VERSION ""

NS_ :

BS_:

BU_: Airbag_MQB BAP_Tester_MQB BMS_MQB Datenlogger_MQB Gateway_MQB Getriebe_DQ_Hybrid_MQB Getriebe_DQ_MQB LEH_MQB Motor_Diesel_MQB Motor_Hybrid_MQB Motor_Otto_MQB SAK_MQB Waehlhebel_MQB Vector__XXX l c i XXX

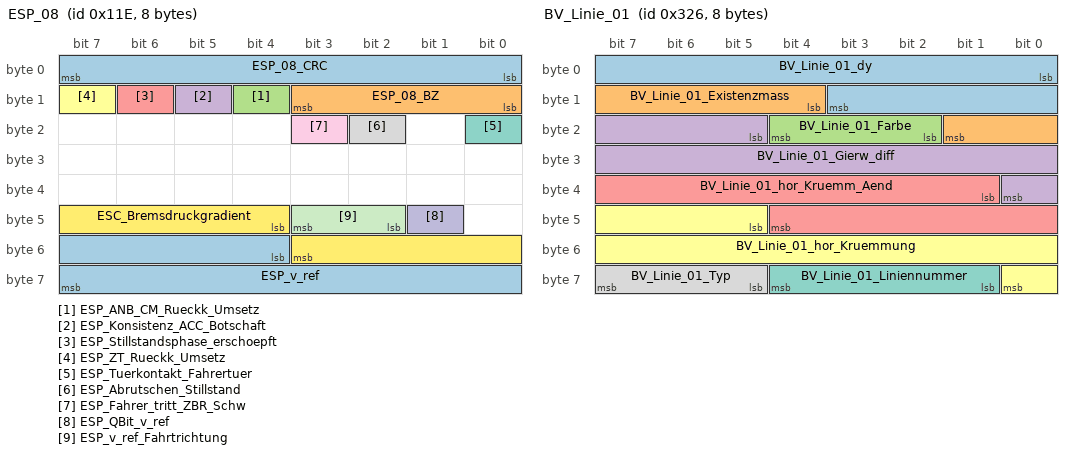
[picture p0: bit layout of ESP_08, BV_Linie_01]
BO_ 286 ESP_08: 8 Gateway_MQB
 SG_ ESP_08_CRC : 0|8@1+ (1,0) [0|255] ""  XXX
 SG_ ESP_08_BZ : 8|4@1+ (1,0) [0|15] ""  XXX
 SG_ ESP_ANB_CM_Rueckk_Umsetz : 12|1@1+ (1.0,0.0) [0.0|1] ""  XXX
 SG_ ESP_Konsistenz_ACC_Botschaft : 13|1@1+ (1.0,0.0) [0.0|1] ""  XXX
 SG_ ESP_Stillstandsphase_erschoepft : 14|1@1+ (1.0,0.0) [0.0|1] ""  XXX
 SG_ ESP_ZT_Rueckk_Umsetz : 15|1@1+ (1.0,0.0) [0.0|1] ""  XXX
 SG_ ESP_Tuerkontakt_Fahrertuer : 16|1@1+ (1.0,0.0) [0.0|1] ""  XXX
 SG_ ESP_Abrutschen_Stillstand : 18|1@1+ (1.0,0.0) [0.0|1] ""  XXX
 SG_ ESP_Fahrer_tritt_ZBR_Schw : 19|1@1+ (1.0,0.0) [0.0|1] ""  XXX
 SG_ ESP_QBit_v_ref : 41|1@1+ (1.0,0.0) [0.0|1] ""  XXX
 SG_ ESP_v_ref_Fahrtrichtung : 42|2@1+ (1.0,0.0) [0.0|3] ""  XXX
 SG_ ESC_Bremsdruckgradient : 44|8@1+ (10,0) [0|2500] "Unit_BarPerSecon"  XXX
 SG_ ESP_v_ref : 52|12@1+ (0.125,0) [0.000|511.500] "Unit_KiloMeterPerHour"  XXX

BO_ 919 LDW_02: 8 XXX
 SG_ LDW_Gong : 12|2@1+ (1,0) [0|3] ""  XXX
 SG_ LDW_Frueh_Spaet : 14|2@1+ (1,0) [0|3] ""  XXX
 SG_ LDW_Texte : 16|4@1+ (1,0) [0|15] ""  XXX
 SG_ LDW_Seite_DLCTLC : 20|1@1+ (1,0) [0|1] ""  XXX
 SG_ LDW_Lernmodus : 21|3@1+ (1,0) [0|7] ""  XXX
 SG_ LDW_Anlaufsp_VLR : 24|4@1+ (1,0) [0|15] ""  XXX
 SG_ LDW_Vib_Amp_VLR : 28|4@1+ (1,0) [0|15] ""  XXX
 SG_ LDW_Anlaufzeit_VLR : 32|4@1+ (1,0) [0|15] ""  XXX
 SG_ LDW_Lernmodus_rechts : 36|2@1+ (1,0) [0|3] ""  XXX
 SG_ LDW_Lernmodus_links : 38|2@1+ (1,0) [0|3] ""  XXX
 SG_ LDW_DLC : 40|8@1+ (0.01,-1.25) [-1.25|1.25] "Unit_Meter"  XXX
 SG_ LDW_TLC : 48|5@1+ (0.1,0) [0|3] "Unit_Secon"  XXX
 SG_ LDW_Warnung_links : 56|1@1+ (1,0) [0|1] ""  XXX
 SG_ LDW_Warnung_rechts : 57|1@1+ (1,0) [0|1] ""  XXX
 SG_ LDW_Codierinfo_fuer_VLR : 58|2@1+ (1,0) [0|3] ""  XXX
 SG_ LDW_Frontscheibenheizung_aktiv : 60|1@1+ (1,0) [0|1] ""  XXX
 SG_ LDW_Status_LED_gelb : 61|1@1+ (1,0) [0|1] ""  XXX
 SG_ LDW_Status_LED_gruen : 62|1@1+ (1,0) [0|1] ""  XXX
 SG_ LDW_KD_Fehler : 63|1@1+ (1,0) [0|1] ""  XXX

BO_ 806 BV_Linie_01: 8 XXX
 SG_ BV_Linie_01_dy : 0|12@1+ (0.00390625,-8) [-8.00000000|7.99609375] "Unit_Meter" XXX
 SG_ BV_Linie_01_Existenzmass : 12|6@1+ (0.015625,0) [0.000000|0.984375] "Unit_Meter" XXX
 SG_ BV_Linie_01_Farbe : 18|3@1+ (1.0,0.0) [0.0|7] "" XXX
 SG_ BV_Linie_01_Gierw_diff : 21|12@1+ (0.00048828125,-1) [-1.00000000000|0.99951171875] "Unit_Radia" XXX
 SG_ BV_Linie_01_hor_Kruemm_Aend : 33|12@1+ (1,-2047) [-2047|2048] "" XXX
 SG_ BV_Linie_01_hor_Kruemmung : 45|12@1+ (1,-2047) [-2047|2048] "" XXX
 SG_ BV_Linie_01_Liniennummer : 57|4@1+ (1,0) [1|15] "" XXX
 SG_ BV_Linie_01_Typ : 61|3@1+ (1.0,0.0) [0.0|7] "" XXX

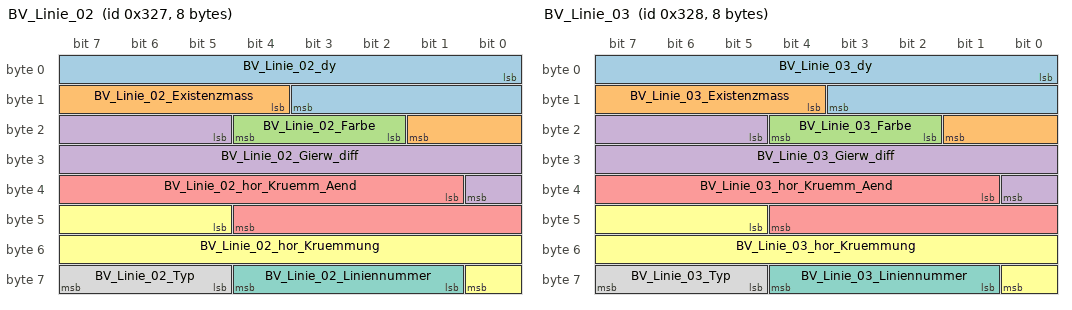
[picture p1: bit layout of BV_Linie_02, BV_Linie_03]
BO_ 807 BV_Linie_02: 8 XXX
 SG_ BV_Linie_02_dy : 0|12@1+ (0.00390625,-8) [-8.00000000|7.99609375] "Unit_Meter" XXX
 SG_ BV_Linie_02_Existenzmass : 12|6@1+ (0.015625,0) [0.000000|0.984375] "Unit_Meter" XXX
 SG_ BV_Linie_02_Farbe : 18|3@1+ (1.0,0.0) [0.0|7] "" XXX
 SG_ BV_Linie_02_Gierw_diff : 21|12@1+ (0.00048828125,-1) [-1.00000000000|0.99951171875] "Unit_Radia" XXX
 SG_ BV_Linie_02_hor_Kruemm_Aend : 33|12@1+ (1,-2047) [-2047|2048] "" XXX
 SG_ BV_Linie_02_hor_Kruemmung : 45|12@1+ (1,-2047) [-2047|2048] "" XXX
 SG_ BV_Linie_02_Liniennummer : 57|4@1+ (1,0) [1|15] "" XXX
 SG_ BV_Linie_02_Typ : 61|3@1+ (1.0,0.0) [0.0|7] "" XXX

BO_ 808 BV_Linie_03: 8 XXX
 SG_ BV_Linie_03_dy : 0|12@1+ (0.00390625,-8) [-8.00000000|7.99609375] "Unit_Meter" XXX
 SG_ BV_Linie_03_Existenzmass : 12|6@1+ (0.015625,0) [0.000000|0.984375] "Unit_Meter" XXX
 SG_ BV_Linie_03_Farbe : 18|3@1+ (1.0,0.0) [0.0|7] "" XXX
 SG_ BV_Linie_03_Gierw_diff : 21|12@1+ (0.00048828125,-1) [-1.00000000000|0.99951171875] "Unit_Radia" XXX
 SG_ BV_Linie_03_hor_Kruemm_Aend : 33|12@1+ (1,-2047) [-2047|2048] "" XXX
 SG_ BV_Linie_03_hor_Kruemmung : 45|12@1+ (1,-2047) [-2047|2048] "" XXX
 SG_ BV_Linie_03_Liniennummer : 57|4@1+ (1,0) [1|15] "" XXX
 SG_ BV_Linie_03_Typ : 61|3@1+ (1.0,0.0) [0.0|7] "" XXX

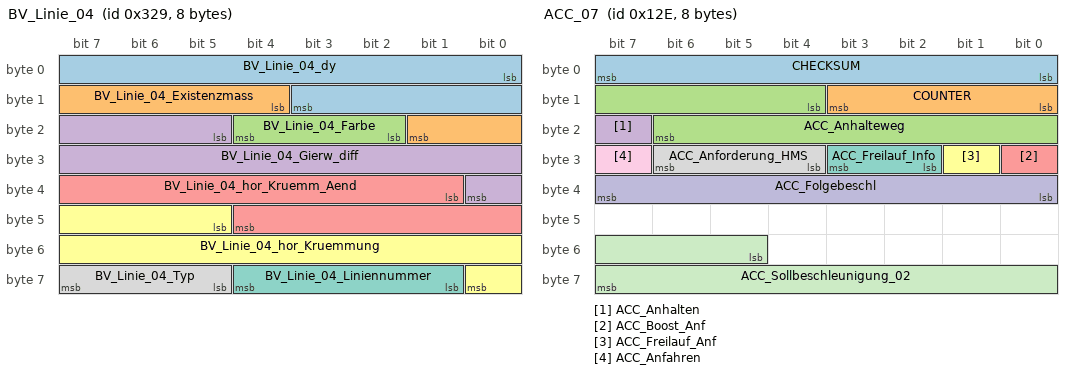
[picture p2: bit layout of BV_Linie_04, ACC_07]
BO_ 809 BV_Linie_04: 8 XXX
 SG_ BV_Linie_04_dy : 0|12@1+ (0.00390625,-8) [-8.00000000|7.99609375] "Unit_Meter" XXX
 SG_ BV_Linie_04_Existenzmass : 12|6@1+ (0.015625,0) [0.000000|0.984375] "Unit_Meter" XXX
 SG_ BV_Linie_04_Farbe : 18|3@1+ (1.0,0.0) [0.0|7] "" XXX
 SG_ BV_Linie_04_Gierw_diff : 21|12@1+ (0.00048828125,-1) [-1.00000000000|0.99951171875] "Unit_Radia" XXX
 SG_ BV_Linie_04_hor_Kruemm_Aend : 33|12@1+ (1,-2047) [-2047|2048] "" XXX
 SG_ BV_Linie_04_hor_Kruemmung : 45|12@1+ (1,-2047) [-2047|2048] "" XXX
 SG_ BV_Linie_04_Liniennummer : 57|4@1+ (1,0) [1|15] "" XXX
 SG_ BV_Linie_04_Typ : 61|3@1+ (1.0,0.0) [0.0|7] "" XXX

BO_ 385 VZE_01: 8 XXX
 SG_ VZE_Anzeigemodus : 0|2@1+ (1.0,0.0) [0.0|3] "" XXX
 SG_ VZE_Hinweistext : 2|3@1+ (1,0) [1|7] "" XXX
 SG_ VZE_Akustik_Limitwechsel : 5|1@1+ (1.0,0.0) [0.0|1] "" XXX
 SG_ VZE_Modus_OptischeWarnung : 6|1@1+ (1.0,0.0) [0.0|1] "" XXX
 SG_ VZE_Anzeigeunterdrueck_Zeichen_3 : 9|1@1+ (1.0,0.0) [0.0|1] "" XXX
 SG_ VZE_Anzeigeunterdrueck_Zeichen_2 : 10|1@1+ (1.0,0.0) [0.0|1] "" XXX
 SG_ VZE_Verkehrszeichen_1 : 11|8@1+ (1,0) [1|255] "" XXX
 SG_ VZE_Verkehrszeichen_2 : 19|8@1+ (1,0) [1|255] "" XXX
 SG_ VZE_Verkehrszeichen_3 : 27|8@1+ (1,0) [1|255] "" XXX
 SG_ VZE_Warnung_Verkehrszeichen_1 : 35|1@1+ (1.0,0.0) [0.0|1] "" XXX
 SG_ VZE_Warnung_Verkehrszeichen_2 : 36|1@1+ (1.0,0.0) [0.0|1] "" XXX
 SG_ VZE_Warnung_Verkehrszeichen_3 : 37|1@1+ (1.0,0.0) [0.0|1] "" XXX
 SG_ VZE_Zusatzschild_1 : 38|4@1+ (1,0) [1|15] "" XXX
 SG_ VZE_Zusatzschild_2 : 42|4@1+ (1,0) [1|15] "" XXX
 SG_ VZE_Zusatzschild_3 : 46|4@1+ (1,0) [1|15] "" XXX
 SG_ VZE_Anzeigeunterdrueck_Zeichen_1 : 50|1@1+ (1.0,0.0) [0.0|1] "" XXX
 SG_ VZE_Zeichen_01_KameraWied : 51|1@1+ (1.0,0.0) [0.0|1] "" XXX
 SG_ VZE_Zeichen_02_KameraWied : 52|1@1+ (1.0,0.0) [0.0|1] "" XXX
 SG_ VZE_Zeichen_03_KameraWied : 53|1@1+ (1.0,0.0) [0.0|1] "" XXX
 SG_ VZE_Zeichen_01_Kamera : 54|1@1+ (1.0,0.0) [0.0|1] "" XXX
 SG_ VZE_Zeichen_01_Karte : 55|1@1+ (1.0,0.0) [0.0|1] "" XXX
 SG_ VZE_Zeichen_01_Gesetz : 56|1@1+ (1.0,0.0) [0.0|1] "" XXX
 SG_ VZE_Zeichen_02_Kamera : 57|1@1+ (1.0,0.0) [0.0|1] "" XXX
 SG_ VZE_Zeichen_02_Karte : 58|1@1+ (1.0,0.0) [0.0|1] "" XXX
 SG_ VZE_Zeichen_02_Gesetz : 59|1@1+ (1.0,0.0) [0.0|1] "" XXX
 SG_ VZE_Zeichen_03_Kamera : 60|1@1+ (1.0,0.0) [0.0|1] "" XXX
 SG_ VZE_Zeichen_03_Karte : 61|1@1+ (1.0,0.0) [0.0|1] "" XXX
 SG_ VZE_Zeichen_03_Gesetz : 62|1@1+ (1.0,0.0) [0.0|1] "" XXX
 SG_ VZE_Gong : 63|1@1+ (1.0,0.0) [0.0|1] "" XXX

BO_ 668 VZE_02: 8 XXX
 SG_ VZE_Akustik_Limitwechsel_Status : 5|1@1+ (1.0,0.0) [0.0|1] "" XXX
 SG_ VZE_SLWF_Status : 6|2@1+ (1.0,0.0) [0.0|3] "" XXX
 SG_ VZE_Anzeigeunterdrueck_Zeichen_5 : 8|1@1+ (1.0,0.0) [0.0|1] "" XXX
 SG_ VZE_Zeichen_05_KameraWied : 9|1@1+ (1.0,0.0) [0.0|1] "" XXX
 SG_ VZE_Zeichen_05_Kamera : 10|1@1+ (1.0,0.0) [0.0|1] "" XXX
 SG_ VZE_Verkehrszeichen_4 : 11|8@1+ (1,0) [1|255] "" XXX
 SG_ VZE_Verkehrszeichen_5 : 19|8@1+ (1,0) [1|255] "" XXX
 SG_ VZE_Anhaenger_Vmax : 27|4@1+ (10,10) [10|140] "Unit_KiloMeterPerHour" XXX
 SG_ VZE_Zeichen_04_Gesetz : 31|1@1+ (1.0,0.0) [0.0|1] "" XXX
 SG_ VZE_Zeichen_04_Kamera : 32|1@1+ (1.0,0.0) [0.0|1] "" XXX
 SG_ VZE_Zeichen_04_KameraWied : 33|1@1+ (1.0,0.0) [0.0|1] "" XXX
 SG_ VZE_Zeichen_04_Karte : 34|1@1+ (1.0,0.0) [0.0|1] "" XXX
 SG_ VZE_Warnung_Verkehrszeichen_4 : 35|1@1+ (1.0,0.0) [0.0|1] "" XXX
 SG_ VZE_Warnung_Verkehrszeichen_5 : 36|1@1+ (1.0,0.0) [0.0|1] "" XXX
 SG_ VZE_Zeichen_05_Gesetz : 37|1@1+ (1.0,0.0) [0.0|1] "" XXX
 SG_ VZE_Zusatzschild_4 : 38|4@1+ (1,0) [1|15] "" XXX
 SG_ VZE_Zusatzschild_5 : 42|4@1+ (1,0) [1|15] "" XXX
 SG_ VZE_Baustelle : 46|2@1+ (1.0,0.0) [0.0|3] "" XXX
 SG_ VZE_Zeichen_05_Karte : 48|1@1+ (1.0,0.0) [0.0|1] "" XXX
 SG_ VZE_Zeichen_05_Entfernung : 49|7@1+ (1,0) [1|127] "Unit_Meter" XXX
 SG_ VZE_Zeichen_05_Entfernung_StdA : 56|7@1+ (1,0) [1|127] "Unit_Meter" XXX
 SG_ VZE_Anzeigeunterdrueck_Zeichen_4 : 63|1@1+ (1.0,0.0) [0.0|1] "" XXX

BO_ 780 ACC_02: 8 XXX
 SG_ CHECKSUM : 0|8@1+ (1,0) [0|255] ""  XXX
 SG_ COUNTER : 8|4@1+ (1,0) [0|15] ""  XXX
 SG_ ACC_Wunschgeschw_02 : 12|10@1+ (0.32,0) [0|327.04] "Unit_KiloMeterPerHour"  XXX
 SG_ ACC_Status_Prim_Anz : 22|2@1+ (1,0) [0|3] ""  XXX
 SG_ ACC_Abstandsindex : 24|10@1+ (1,0) [1|1021] ""  XXX
 SG_ ACC_Akustik_02 : 34|2@1+ (1,0) [0|3] ""  XXX
 SG_ ACC_Warnung_Verkehrszeichen_1 : 36|1@1+ (1,0) [0|1] ""  XXX
 SG_ ACC_Gesetzte_Zeitluecke : 37|3@1+ (1,0) [0|7] ""  XXX
 SG_ ACC_Optischer_Fahrerhinweis : 40|1@1+ (1,0) [0|1] ""  XXX
 SG_ ACC_Typ_Tachokranz : 41|1@1+ (1,0) [0|1] ""  XXX
 SG_ ACC_Anzeige_Zeitluecke : 42|1@1+ (1,0) [0|1] ""  XXX
 SG_ ACC_Tachokranz : 43|1@1+ (1,0) [0|1] ""  XXX
 SG_ ACC_Display_Prio : 44|2@1+ (1,0) [0|3] ""  XXX
 SG_ ACC_Relevantes_Objekt : 46|2@1+ (1,0) [0|3] ""  XXX
 SG_ ACC_Texte_Primaeranz : 48|7@1+ (1,0) [0|127] ""  XXX
 SG_ ACC_Wunschgeschw_erreicht : 55|1@1+ (1,0) [0|1] ""  XXX
 SG_ ACC_Typ_Tachokranz_unten : 60|1@1+ (1,0) [0|1] ""  XXX
 SG_ ACC_Status_Anzeige : 61|3@1+ (1,0) [0|7] ""  XXX

BO_ 302 ACC_07: 8 XXX
 SG_ CHECKSUM : 0|8@1+ (1,0) [0|255] ""  XXX
 SG_ COUNTER : 8|4@1+ (1,0) [0|15] ""  XXX
 SG_ ACC_Anhalteweg : 12|11@1+ (0.01,0) [0|20.45] "Unit_Meter"  XXX
 SG_ ACC_Anhalten : 23|1@1+ (1,0) [0|1] ""  XXX
 SG_ ACC_Boost_Anf : 24|1@1+ (1,0) [0|1] ""  XXX
 SG_ ACC_Freilauf_Anf : 25|1@1+ (1,0) [0|1] ""  XXX
 SG_ ACC_Freilauf_Info : 26|2@1+ (1,0) [0|3] ""  XXX
 SG_ ACC_Anforderung_HMS : 28|3@1+ (1,0) [0|7] ""  XXX
 SG_ ACC_Anfahren : 31|1@1+ (1,0) [0|1] ""  XXX
 SG_ ACC_Folgebeschl : 32|8@1+ (0.03,-4.6) [-4.6|2.99] "Unit_MeterPerSeconSquar"  XXX
 SG_ ACC_Sollbeschleunigung_02 : 53|11@1+ (0.005,-7.22) [-7.22|3.005] "Unit_MeterPerSeconSquar"  XXX

BO_ 264 Fahrwerk_01: 8 XXX
 SG_ Fahrwerk_01_BZ : 8|4@1+ (1,0) [0|15] "" XXX
 SG_ Fahrwerk_01_CRC : 0|8@1+ (1,0) [0|255] "" XXX

BO_ 695 RCTA_01: 8 XXX
 SG_ RCTA_01_BZ : 8|4@1+ (1,0) [0|15] "" XXX
 SG_ RCTA_01_CRC : 0|8@1+ (1,0) [0|255] "" XXX

BO_ 783 SWA_01: 8 Gateway_MQB
 SG_ CHECKSUM : 0|8@1+ (1,0) [0|255] ""  XXX
 SG_ COUNTER : 8|4@1+ (1,0) [0|15] ""  XXX
 SG_ SWA_Anzeigen : 12|4@1+ (1,0) [0|15] ""  XXX
 SG_ SWA_Blindheit_erkannt : 16|1@1+ (1,0) [0|1] ""  XXX
 SG_ SWA_rel_Nichtverf : 17|1@1+ (1,0) [0|1] ""  XXX
 SG_ SWA_rel_Fehler : 18|1@1+ (1,0) [0|1] ""  XXX
 SG_ SWA_Sta_aktiv : 19|1@1+ (1,0) [0|1] ""  XXX
 SG_ SWA_Sta_passiv : 20|1@1+ (1,0) [0|1] ""  XXX
 SG_ SWA_FT_RueckLED : 21|1@1+ (1,0) [0|1] ""  XXX
 SG_ ASW_Status : 22|2@1+ (1,0) [0|3] ""  XXX
 SG_ SWA_Standziele_li : 24|1@1+ (1,0) [0|1] ""  XXX
 SG_ SWA_Kolonne_li : 25|1@1+ (1,0) [0|1] ""  XXX
 SG_ SWA_Infostufe_SWA_li : 26|1@1+ (1,0) [0|1] ""  XXX
 SG_ SWA_Warnung_SWA_li : 27|1@1+ (1,0) [0|1] ""  XXX
 SG_ ASW_Warnung_FS : 28|1@1+ (1,0) [0|1] ""  XXX
 SG_ ASW_Warnung_BFS : 29|1@1+ (1,0) [0|1] ""  XXX
 SG_ ASW_Kombitexte : 30|3@1+ (1,0) [0|7] ""  XXX
 SG_ SWA_Kolonne_mi : 33|1@1+ (1,0) [0|1] ""  XXX
 SG_ SWA_Standziele_re : 40|1@1+ (1,0) [0|1] ""  XXX
 SG_ SWA_Kolonne_re : 41|1@1+ (1,0) [0|1] ""  XXX
 SG_ SWA_Infostufe_SWA_re : 42|1@1+ (1,0) [0|1] ""  XXX
 SG_ SWA_Warnung_SWA_re : 43|1@1+ (1,0) [0|1] ""  XXX
 SG_ HRE_Anzeigetexte : 44|4@1+ (1,0) [0|15] ""  XXX
 SG_ SWA_Gischtzaehler : 48|7@1+ (1,0) [0|100] "Unit_PerCent"  XXX
 SG_ Heckradar_Kombitexte : 56|5@1+ (1,0) [0|31] ""  XXX
 SG_ RCTA_Kombitexte : 61|3@1+ (1,0) [0|7] ""  XXX

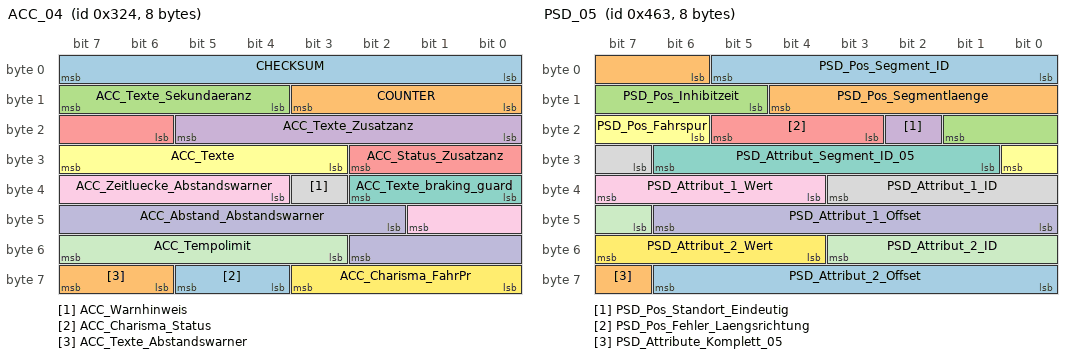
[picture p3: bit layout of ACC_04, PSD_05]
BO_ 804 ACC_04: 8 XXX
 SG_ CHECKSUM : 0|8@1+ (1,0) [0|255] ""  XXX
 SG_ COUNTER : 8|4@1+ (1,0) [0|15] ""  XXX
 SG_ ACC_Texte_Sekundaeranz : 12|4@1+ (1,0) [0|15] ""  XXX
 SG_ ACC_Texte_Zusatzanz : 16|6@1+ (1,0) [0|63] ""  XXX
 SG_ ACC_Status_Zusatzanz : 22|5@1+ (1,0) [0|31] ""  XXX
 SG_ ACC_Texte : 27|5@1+ (1,0) [0|31] ""  XXX
 SG_ ACC_Texte_braking_guard : 32|3@1+ (1,0) [0|7] ""  XXX
 SG_ ACC_Warnhinweis : 35|1@1+ (1,0) [0|1] ""  XXX
 SG_ ACC_Zeitluecke_Abstandswarner : 36|6@1+ (0.1,0) [0|6] "Unit_Secon"  XXX
 SG_ ACC_Abstand_Abstandswarner : 42|9@1+ (1,0) [0|508] ""  XXX
 SG_ ACC_Tempolimit : 51|5@1+ (1,0) [0|31] ""  XXX
 SG_ ACC_Charisma_FahrPr : 56|4@1+ (1,0) [0|15] ""  XXX
 SG_ ACC_Charisma_Status : 60|2@1+ (1,0) [0|3] ""  XXX
 SG_ ACC_Texte_Abstandswarner : 62|2@1+ (1,0) [0|3] ""  XXX

BO_ 917 LWR_AFS_01: 8 XXX

BO_ 991 Gateway_76: 8 XXX

BO_ 997 TSG_FT_02: 8 XXX
 SG_ TSG_FT_02_BZ : 8|4@1+ (1,0) [0|15] "" XXX
 SG_ TSG_FT_02_CRC : 0|8@1+ (1,0) [0|255] "" XXX

BO_ 1175 Parkhilfe_01: 8 XXX
 SG_ PH_Visualisierung : 0|3@1+ (1.0,0.0) [0.0|7] "" XXX
 SG_ PDC_Tonausgabe_Front : 4|4@1+ (1.0,0.0) [0.0|15] "" XXX
 SG_ PDC_Tonausgabe_Heck : 8|4@1+ (1.0,0.0) [0.0|15] "" XXX
 SG_ PH_nachtr_Stopp_Anf : 12|1@1+ (1.0,0.0) [0.0|1] "" XXX
 SG_ PH_Abschaltursache : 13|3@1+ (1.0,0.0) [0.0|7] "" XXX
 SG_ PH_Opt_Anzeige_V_ein : 16|1@1+ (1.0,0.0) [0.0|1] "" XXX
 SG_ PH_Opt_Anzeige_H_ein : 17|1@1+ (1.0,0.0) [0.0|1] "" XXX
 SG_ PH_Opt_Anz_V_Hindernis : 18|1@1+ (1.0,0.0) [0.0|1] "" XXX
 SG_ PH_Opt_Anz_H_Hindernis : 19|1@1+ (1.0,0.0) [0.0|1] "" XXX
 SG_ PH_Tongeber_V_aktiv : 20|1@1+ (1.0,0.0) [0.0|1] "" XXX
 SG_ PH_Tongeber_H_aktiv : 21|1@1+ (1.0,0.0) [0.0|1] "" XXX
 SG_ PH_Tongeber_mute : 22|1@1+ (1.0,0.0) [0.0|1] "" XXX
 SG_ PH_Anf_Audioabsenkung : 23|1@1+ (1.0,0.0) [0.0|1] "" XXX
 SG_ PH_Tongeber_H_verfuegbar : 24|1@1+ (1.0,0.0) [0.0|1] "" XXX
 SG_ PLA_Anf_Aufschaltung_RVC : 25|1@1+ (1.0,0.0) [0.0|1] "" XXX
 SG_ PH_Taster : 28|2@1+ (1.0,0.0) [0.0|3] "" XXX
 SG_ PH_Anf_Verdeck : 30|2@1+ (1.0,0.0) [0.0|3] "" XXX
 SG_ PH_Frequenz_hinten : 32|4@1+ (1,0) [0|15] "" XXX
 SG_ PH_Lautstaerke_hinten : 36|4@1+ (1,0) [0|15] "" XXX
 SG_ PH_Frequenz_vorn : 40|4@1+ (1,0) [0|15] "" XXX
 SG_ PH_Lautstaerke_vorn : 44|4@1+ (1,0) [0|15] "" XXX
 SG_ PH_StartStopp_Info : 49|2@1+ (1.0,0.0) [0.0|3] "" XXX
 SG_ PH_Stoermeldung : 52|4@1+ (1.0,0.0) [0.0|15] "" XXX
 SG_ PH_defekt : 56|1@1+ (1.0,0.0) [0.0|1] "" XXX
 SG_ PH_gestoert : 57|1@1+ (1.0,0.0) [0.0|1] "" XXX
 SG_ PH_Systemzustand : 58|3@1+ (1.0,0.0) [0.0|7] "" XXX
 SG_ PH_Display_Kundenwunsch : 61|2@1+ (1.0,0.0) [0.0|3] "" XXX

BO_ 427 ESP_33: 8 Gateway_MQB
 SG_ CHECKSUM : 0|8@1+ (1,0) [0|255] ""  Motor_Hybrid_MQB,Motor_Otto_MQB
 SG_ COUNTER : 8|4@1+ (1,0) [0|15] ""  Motor_Hybrid_MQB,Motor_Otto_MQB
 SG_ ESC_AHW_aktiv : 12|3@1+ (1,0) [0|7] ""  Motor_Hybrid_MQB,Motor_Otto_MQB
 SG_ ESC_AHW_nicht_verfuegbar : 15|1@1+ (1,0) [0|1] ""  Vector__XXX
 SG_ ESC_ANB_CM_aktiv : 16|2@1+ (1,0) [0|3] ""  Motor_Hybrid_MQB,Motor_Otto_MQB
 SG_ ESC_ANB_CM_nicht_verfuegbar : 18|1@1+ (1,0) [0|1] ""  Vector__XXX
 SG_ ESC_Warnruck_aktiv : 19|4@1+ (1,0) [0|15] ""  Motor_Hybrid_MQB,Motor_Otto_MQB
 SG_ ESC_Warnruck_nicht_verfuegbar : 23|1@1+ (1,0) [0|1] ""  Vector__XXX
 SG_ ESC_Prefill_aktiv : 24|1@1+ (1,0) [0|1] ""  Vector__XXX
 SG_ ESC_Prefill_nicht_verfuegbar : 25|1@1+ (1,0) [0|1] ""  Vector__XXX
 SG_ ESC_HBA_aktiv : 26|1@1+ (1,0) [0|1] ""  Airbag_MQB
 SG_ ESC_HBA_nicht_verfuegbar : 27|1@1+ (1,0) [0|1] ""  Airbag_MQB
 SG_ ESC_TSK_SRBM_Anf : 28|1@1+ (1,0) [0|1] ""  Motor_Hybrid_MQB,Motor_Otto_MQB
 SG_ ESC_TSK_SRBM_nicht_verfuegbar : 29|1@1+ (1,0) [0|1] ""  Motor_Hybrid_MQB,Motor_Otto_MQB
 SG_ ESC_Verz_Reg_aktiv : 30|4@1+ (1,0) [0|15] ""  Airbag_MQB,Motor_Hybrid_MQB,Motor_Otto_MQB
 SG_ ESC_Verz_Reg_nicht_verfuegbar : 34|1@1+ (1,0) [0|1] ""  Airbag_MQB,Motor_Hybrid_MQB,Motor_Otto_MQB
 SG_ ESC_Verz_Reg_TB_nicht_verfuegbar : 35|1@1+ (1,0) [0|1] ""  Vector__XXX
 SG_ ESC_Verz_Reg_ZB_nicht_verfuegbar : 36|1@1+ (1,0) [0|1] ""  Vector__XXX
 SG_ ESC_Bremslicht_unplausibel : 37|1@1+ (1,0) [0|1] ""  Motor_Hybrid_MQB,Motor_Otto_MQB
 SG_ ESC_Konsistenz_ACC : 38|1@1+ (1,0) [0|1] ""  Vector__XXX
 SG_ ESC_Konsistenz_AWV : 39|1@1+ (1,0) [0|1] ""  Vector__XXX
 SG_ ESC_Konsistenz_ARA : 40|1@1+ (1,0) [0|1] ""  Vector__XXX
 SG_ ESC_Konsistenz_IPA : 41|1@1+ (1,0) [0|1] ""  Vector__XXX
 SG_ ESC_Konsistenz_FCW : 42|1@1+ (1,0) [0|1] ""  Vector__XXX
 SG_ ESC_Konsistenz_NV : 43|1@1+ (1,0) [0|1] ""  Vector__XXX
 SG_ ESC_Konsistenz_RCTA : 44|1@1+ (1,0) [0|1] ""  Vector__XXX
 SG_ ESC_Konsistenz_TSK : 45|1@1+ (1,0) [0|1] ""  Motor_Hybrid_MQB,Motor_Otto_MQB
 SG_ ESC_Konsistenz_vFGS : 46|1@1+ (1,0) [0|1] ""  Vector__XXX
 SG_ ESC_Konsistenz_STA : 47|1@1+ (1,0) [0|1] ""  Vector__XXX
 SG_ ESC_Fahrer_Bremsdruck_bestimmend : 48|1@1+ (1,0) [0|1] ""  Motor_Hybrid_MQB,Motor_Otto_MQB
 SG_ ESC_Konsistenz_EA : 49|1@1+ (1,0) [0|1] ""  Vector__XXX
 SG_ ESC_Konsistenz_BFF : 50|1@1+ (1,0) [0|1] ""  Vector__XXX
 SG_ ESC_Konsistenz_MKB : 51|1@1+ (1,0) [0|1] ""  Airbag_MQB
 SG_ ESC_Verz_ASIL_Verfuegbarkeit : 52|3@1+ (1,0) [0|7] ""  Airbag_MQB,Motor_Hybrid_MQB,Motor_Otto_MQB
 SG_ ESC_Pumpenanlauf_aktiv : 55|1@1+ (1,0) [0|1] ""  Vector__XXX
 SG_ ESC_Konsistenz_AGW : 56|1@1+ (1,0) [0|1] ""  Vector__XXX
 SG_ ESC_Konsistenz_KAS : 57|1@1+ (1,0) [0|1] ""  Vector__XXX
 SG_ ESC_Konsistenz_PCF : 58|1@1+ (1,0) [0|1] ""  Vector__XXX
 SG_ ESC_Konsistenz_FAS_VK : 59|1@1+ (1,0) [0|1] ""  Vector__XXX
 SG_ ESC_Verz_Begrenzung : 60|1@1+ (1,0) [0|1] ""  Vector__XXX
 SG_ ESC_Konsistenz_AWA : 61|1@1+ (1,0) [0|1] ""  Vector__XXX

BO_ 418 ESP_15: 8 XXX
 SG_ ESP_15_CRC : 0|8@1+ (1,0) [0|255] "" XXX
 SG_ ESP_15_BZ : 8|4@1+ (1,0) [0|15] "" XXX

BO_ 1122 PSD_04: 8 XXX
 SG_ PSD_Segment_ID : 0|6@1+ (1,0) [2|63] ""  XXX
 SG_ PSD_Vorgaenger_Segment_ID : 6|6@1+ (1,0) [2|63] ""  XXX
 SG_ PSD_Segmentlaenge : 12|7@1+ (2,0) [0|254] "Unit_Meter"  XXX
 SG_ PSD_Strassenkategorie : 19|3@1+ (1,0) [0|7] ""  XXX
 SG_ PSD_Endkruemmung : 22|8@1+ (1,0) [0|254] "Unit_None"  XXX
 SG_ PSD_Endkruemmung_Vorz : 30|1@1+ (1,0) [0|1] ""  XXX
 SG_ PSD_Idenditaets_ID : 31|6@1+ (1,0) [2|63] ""  XXX
 SG_ PSD_ADAS_Qualitaet : 37|1@1+ (1,0) [0|1] ""  XXX
 SG_ PSD_wahrscheinlichster_Pfad : 38|1@1+ (1,0) [0|1] ""  XXX
 SG_ PSD_Geradester_Pfad : 39|1@1+ (1,0) [0|1] ""  XXX
 SG_ PSD_Fahrspuren_Anzahl : 40|3@1+ (1,0) [0|7] ""  XXX
 SG_ PSD_Bebauung : 43|1@1+ (1,0) [0|1] ""  XXX
 SG_ PSD_Segment_Komplett : 44|1@1+ (1,0) [0|1] ""  XXX
 SG_ PSD_Rampe : 45|2@1+ (1,0) [0|3] ""  XXX
 SG_ PSD_Anfangskruemmung : 47|8@1+ (1,0) [0|254] ""  XXX
 SG_ PSD_Anfangskruemmung_Vorz : 55|1@1+ (1,0) [0|1] ""  XXX
 SG_ PSD_Abzweigerichtung : 56|1@1+ (1,0) [0|1] ""  XXX
 SG_ PSD_Abzweigewinkel : 57|7@1+ (1.417323,0) [0|180.000021] ""  XXX

BO_ 1123 PSD_05: 8 XXX
 SG_ PSD_Pos_Segment_ID : 0|6@1+ (1,0) [2|63] ""  XXX
 SG_ PSD_Pos_Segmentlaenge : 6|7@1+ (2,0) [0|254] "Unit_Meter"  XXX
 SG_ PSD_Pos_Inhibitzeit : 13|5@1+ (10,0) [0|310] "Unit_MilliSecon"  XXX
 SG_ PSD_Pos_Standort_Eindeutig : 18|1@1+ (1,0) [0|1] ""  XXX
 SG_ PSD_Pos_Fehler_Laengsrichtung : 19|3@1+ (1,0) [0|7] ""  XXX
 SG_ PSD_Pos_Fahrspur : 22|3@1+ (1,0) [0|7] ""  XXX
 SG_ PSD_Attribut_Segment_ID_05 : 25|6@1+ (1,0) [2|63] ""  XXX
 SG_ PSD_Attribut_1_ID : 31|5@1+ (1,0) [1|31] ""  XXX
 SG_ PSD_Attribut_1_Wert : 36|4@1+ (1,0) [0|15] ""  XXX
 SG_ PSD_Attribut_1_Offset : 40|7@1+ (2,0) [0|254] "Unit_Meter"  XXX
 SG_ PSD_Attribut_2_ID : 47|5@1+ (1,0) [1|31] ""  XXX
 SG_ PSD_Attribut_2_Wert : 52|4@1+ (1,0) [0|15] ""  XXX
 SG_ PSD_Attribut_2_Offset : 56|7@1+ (2,0) [0|254] "Unit_Meter"  XXX
 SG_ PSD_Attribute_Komplett_05 : 63|1@1+ (1,0) [0|1] ""  XXX

BO_ 1124 PSD_06: 8 XXX
 SG_ PSD_06_Mux M : 0|3@1+ (1,0) [0|7] ""  XXX
 SG_ PSD_Sys_Segment_ID m0 : 3|6@1+ (1,0) [2|63] ""  XXX
 SG_ PSD_Sys_Laendercode m0 : 9|8@1+ (1,0) [0|255] ""  XXX
 SG_ PSD_Sys_Geschwindigkeit_Einheit m0 : 17|1@1+ (1,0) [0|1] ""  XXX
 SG_ PSD_Sys_Verkehrsrichtung m0 : 18|1@1+ (1,0) [0|1] ""  XXX
 SG_ PSD_Sys_Geometrieguete m0 : 19|2@1+ (1,0) [0|3] ""  XXX
 SG_ PSD_Sys_Mapmatchingguete m0 : 21|2@1+ (1,0) [0|3] ""  XXX
 SG_ PSD_Sys_Alter_Karte m0 : 23|3@1+ (1,0) [0|7] ""  XXX
 SG_ PSD_Sys_Zielfuehrung m0 : 26|1@1+ (1,0) [0|1] ""  XXX
 SG_ PSD_Sys_US_State m0 : 27|6@1+ (1,0) [0|63] ""  XXX
 SG_ PSD_Sys_Quali_Geometrien m0 : 33|3@1+ (1,0) [0|7] "Unit_None"  XXX
 SG_ PSD_Sys_Quali_Ortsinfo m0 : 36|2@1+ (1,0) [0|3] "Unit_None"  XXX
 SG_ PSD_Sys_Quali_verfuegbar m0 : 38|1@1+ (1,0) [0|1] ""  XXX
 SG_ PSD_Sys_Zielfuehrung_geaendert m0 : 39|1@1+ (1,0) [0|1] ""  XXX
 SG_ PSD_Sys_Geometrieguete_erweitert m0 : 40|8@1+ (1,0) [0|255] ""  XXX
 SG_ PSD_Sys_Quali_sonstige_Attribute m0 : 48|3@1+ (1,0) [0|7] "Unit_None"  XXX
 SG_ PSD_Sys_Quali_Steigungen m0 : 51|3@1+ (1,0) [0|7] ""  XXX
 SG_ PSD_Sys_Quali_Strassenkennz m0 : 54|3@1+ (1,0) [0|7] "Unit_None"  XXX
 SG_ PSD_Sys_Quali_Tempolimits m0 : 57|3@1+ (1,0) [0|7] "Unit_None"  XXX
 SG_ PSD_Sys_Quali_Vorfahrtsregelung m0 : 60|3@1+ (1,0) [0|7] "Unit_None"  XXX
 SG_ PSD_Attribut_Segment_ID m1 : 3|6@1+ (1,0) [2|63] ""  XXX
 SG_ PSD_Attribut_3_ID m1 : 9|5@1+ (1,0) [1|31] ""  XXX
 SG_ PSD_Attribut_3_Offset m1 : 14|7@1+ (2,0) [0|254] "Unit_Meter"  XXX
 SG_ PSD_Attribut_3_Wert m1 : 21|4@1+ (1,0) [0|15] ""  XXX
 SG_ PSD_Attribut_4_ID m1 : 25|5@1+ (1,0) [1|31] ""  XXX
 SG_ PSD_Attribut_4_Wert m1 : 30|4@1+ (1,0) [0|15] ""  XXX
 SG_ PSD_Attribut_4_Offset m1 : 34|7@1+ (2,0) [0|254] "Unit_Meter"  XXX
 SG_ PSD_Attribut_5_ID m1 : 41|5@1+ (1,0) [1|31] ""  XXX
 SG_ PSD_Attribut_5_Offset m1 : 46|7@1+ (2,0) [0|254] "Unit_Meter"  XXX
 SG_ PSD_Attribut_5_Wert m1 : 53|4@1+ (1,0) [0|15] ""  XXX
 SG_ PSD_Attribute_Komplett_06 m1 : 57|1@1+ (1,0) [0|1] ""  XXX
 SG_ PSD_Ges_Segment_ID m2 : 3|6@1+ (1,0) [2|63] ""  XXX
 SG_ PSD_Ges_Offset m2 : 9|7@1+ (2,0) [0|254] "Unit_Meter"  XXX
 SG_ PSD_Ges_Geschwindigkeit m2 : 16|5@1+ (1,0) [0|31] ""  XXX
 SG_ PSD_Ges_Typ m2 : 21|2@1+ (1,0) [0|3] ""  XXX
 SG_ PSD_Ges_Spur_Geschw_Begrenzung m2 : 23|6@1+ (1,0) [0|63] ""  XXX
 SG_ PSD_Ges_Geschwindigkeit_Gespann m2 : 29|2@1+ (1,0) [0|3] ""  XXX
 SG_ PSD_Ges_Geschwindigkeit_Witter m2 : 31|2@1+ (1,0) [0|3] ""  XXX
 SG_ PSD_Ges_Geschwindigkeit_Tag_Anf m2 : 33|3@1+ (1,0) [0|7] ""  XXX
 SG_ PSD_Ges_Geschwindigkeit_Tag_Ende m2 : 36|3@1+ (1,0) [0|7] ""  XXX
 SG_ PSD_Ges_Geschwindigkeit_Std_Anf m2 : 39|5@1+ (1,0) [0|24] "Unit_Hours"  XXX
 SG_ PSD_Ges_Geschwindigkeit_Std_Ende m2 : 44|5@1+ (1,0) [0|24] "Unit_Hours"  XXX
 SG_ PSD_Ges_Ueberholverbot m2 : 49|2@1+ (1,0) [0|3] ""  XXX
 SG_ PSD_Ges_Wechselverkehrszeichen m2 : 51|3@1+ (1,0) [0|7] ""  XXX
 SG_ PSD_Wechselverkehrszeichen_Typ m2 : 54|2@1+ (1,0) [0|3] ""  XXX
 SG_ PSD_Ges_Gesetzlich_Kategorie m2 : 56|3@1+ (1,0) [0|7] ""  XXX
 SG_ PSD_Ges_Gesetzlich_Zusatz m2 : 59|2@1+ (1,0) [0|3] ""  XXX
 SG_ PSD_Ges_Verkehrszeichen_Quelle m2 : 61|2@1+ (1,0) [0|3] ""  XXX
 SG_ PSD_Ges_Attribute_Komplett m2 : 63|1@1+ (1,0) [0|1] ""  XXX
 SG_ PSD_Baum_Laenge_VZ m3 : 3|1@1+ (1,0) [0|1] ""  XXX
 SG_ PSD_Baum_Laenge m3 : 4|25@1+ (1e-05,0) [0|180] "Unit_DegreOfArc"  XXX
 SG_ PSD_Baum_Breite_VZ m3 : 29|1@1+ (1,0) [0|1] ""  XXX
 SG_ PSD_Baum_Breite m3 : 30|24@1+ (1e-05,0) [0|90] "Unit_DegreOfArc"  XXX
 SG_ PSD_Baum_Ausrichtung m3 : 54|10@1+ (0.3515625,0) [0|359.6484375] "Unit_DegreOfArc"  XXX
 SG_ PSD_Steigung_1_Segment_ID m4 : 3|6@1+ (1,0) [2|63] ""  XXX
 SG_ PSD_Steigung_1_A_Steigung m4 : 9|7@1+ (0.12,0) [0|15] "Unit_PerCent"  XXX
 SG_ PSD_Steigung_1_A_Vorz m4 : 16|1@1+ (1,0) [0|1] ""  XXX
 SG_ PSD_Steigung_1_A_Offset m4 : 17|7@1+ (2,0) [0|254] "Unit_Meter"  XXX
 SG_ PSD_Steigung_1_B_Steigung m4 : 24|7@1+ (0.12,0) [0|15] "Unit_PerCent"  XXX
 SG_ PSD_Steigung_1_B_Vorz m4 : 31|1@1+ (1,0) [0|1] ""  XXX
 SG_ PSD_Steigung_1_B_Offset m4 : 32|7@1+ (2,0) [0|254] "Unit_Meter"  XXX
 SG_ PSD_Steigung_1_Attribute_kompl m4 : 39|1@1+ (1,0) [0|1] ""  XXX
 SG_ PSD_Steigung_2_Segment_ID m4 : 40|6@1+ (1,0) [2|63] ""  XXX
 SG_ PSD_Steigung_2_Steigung m4 : 46|7@1+ (0.12,0) [0|15] "Unit_PerCent"  XXX
 SG_ PSD_Steigung_2_Vorz m4 : 53|1@1+ (1,0) [0|1] ""  XXX
 SG_ PSD_Steigung_2_Offset m4 : 54|7@1+ (2,0) [0|254] "Unit_Meter"  XXX
 SG_ PSD_Steigung_2_Attribute_kompl m4 : 61|1@1+ (1,0) [0|1] ""  XXX

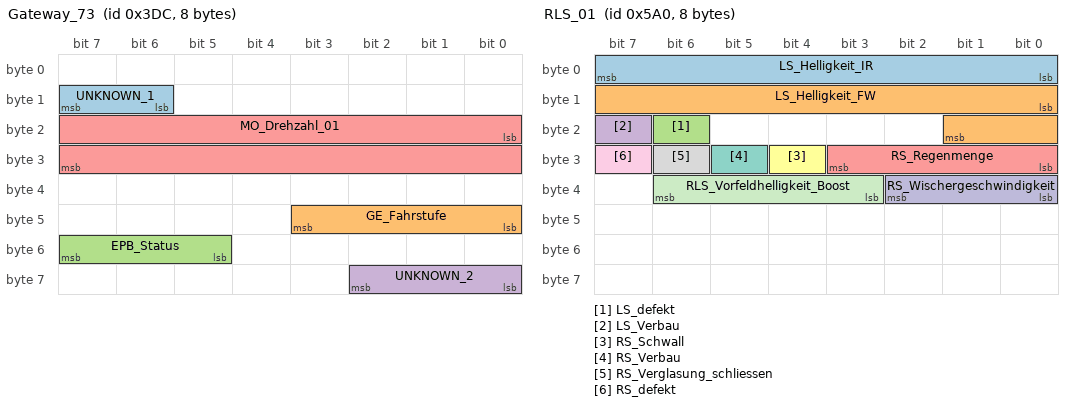
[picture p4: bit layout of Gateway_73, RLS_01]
BO_ 988 Gateway_73: 8 XXX
 SG_ UNKNOWN_1 : 15|2@0+ (1,0) [0|3] "" XXX
 SG_ GE_Fahrstufe : 40|4@1+ (1,0) [0|15] "" XXX
 SG_ EPB_Status : 53|3@1+ (1,0) [0|7] "" XXX
 SG_ UNKNOWN_2 : 58|3@0+ (1,0) [0|7] "" XXX
 SG_ MO_Drehzahl_01 : 16|16@1+ (0.25,0) [0.00|16383.00] "Unit_MinutInver" XXX

BO_ 792 Kamera_Status: 8 XXX

BO_ 981 Licht_Anf_01: 8 Vector__XXX
 SG_ CHECKSUM : 0|8@1+ (1,0) [0|255] "" Vector__XXX
 SG_ COUNTER : 8|4@1+ (1,0) [0|15] "" Vector__XXX
 SG_ BCM1_Kurvenlicht_links_Anf : 12|1@1+ (1,0) [0|1] "" Vector__XXX
 SG_ BCM1_Kurvenlicht_rechts_Anf : 13|1@1+ (1,0) [0|1] "" Vector__XXX
 SG_ BCM1_Standlicht_Anf : 14|1@1+ (1,0) [0|1] "" Vector__XXX
 SG_ BCM1_Abblendlicht_Anf : 15|1@1+ (1,0) [0|1] "" Vector__XXX
 SG_ BCM1_Fernlicht_Anf : 16|1@1+ (1,0) [0|1] "" Vector__XXX
 SG_ BCM1_Nebellicht_Anf : 17|1@1+ (1,0) [0|1] "" Vector__XXX
 SG_ BCM1_Parklicht_li_Anf : 18|1@1+ (1,0) [0|1] "" Vector__XXX
 SG_ BCM1_Parklicht_re_Anf : 19|1@1+ (1,0) [0|1] "" Vector__XXX
 SG_ BCM1_Nebelschluss_Ahg_Anf : 20|1@1+ (1,0) [0|1] "" Vector__XXX
 SG_ BCM1_Nebelschluss_Fzg_Anf : 21|1@1+ (1,0) [0|1] "" Vector__XXX
 SG_ BCM1_Schlusslicht_Anf : 22|1@1+ (1,0) [0|1] "" Vector__XXX
 SG_ BCM_Rueckfahrlicht_Anf : 23|1@1+ (1,0) [0|1] "" Vector__XXX
 SG_ BCM1_Signaturlicht_Anf : 24|1@1+ (1,0) [0|1] "" Vector__XXX
 SG_ BCM1_Umfeldleuchten_Anf : 25|1@1+ (1,0) [0|1] "" Vector__XXX
 SG_ BCM1_Tagfahrlicht_Anf : 26|1@1+ (1,0) [0|1] "" Vector__XXX
 SG_ BCM1_Regenlicht_Anf : 27|1@1+ (1,0) [0|1] "" Vector__XXX
 SG_ BCM1_Autobahnlicht_Anf : 28|1@1+ (1,0) [0|1] "" Vector__XXX
 SG_ BCM1_Touristen_Licht_Anf : 29|1@1+ (1,0) [0|1] ""  Frontradar
 SG_ BCM1_CH_aktiv : 30|1@1+ (1,0) [0|1] "" Vector__XXX
 SG_ BCM1_LH_aktiv : 31|1@1+ (1,0) [0|1] "" Vector__XXX
 SG_ BCM1_Gleitende_Leuchtw_Anf : 32|1@1+ (1,0) [0|1] "" Vector__XXX
 SG_ BCM1_GLW_Fernlicht_Anf : 33|1@1+ (1,0) [0|1] "" Vector__XXX
 SG_ BCM1_Adaptive_Lichtvert_Anf : 34|1@1+ (1,0) [0|1] "" Vector__XXX
 SG_ BCM1_CH_LH_aktiv : 40|1@1+ (1,0) [0|1] "" Vector__XXX
 SG_ BCM1_Allwetterlicht_Anf : 41|1@1+ (1,0) [0|1] ""  Frontradar

BO_ 1440 RLS_01: 8 XXX
 SG_ LS_Helligkeit_IR : 0|8@1+ (400,0) [0|101200] "Unit_Lux" XXX
 SG_ LS_Helligkeit_FW : 8|10@1+ (6,0) [0|6126] "Unit_Lux" XXX
 SG_ LS_defekt : 22|1@1+ (1.0,0.0) [0.0|1] "" XXX
 SG_ LS_Verbau : 23|1@1+ (1.0,0.0) [0.0|1] "" XXX
 SG_ RS_Regenmenge : 24|4@1+ (1.0,0.0) [0.0|15] "" XXX
 SG_ RS_Schwall : 28|1@1+ (1.0,0.0) [0.0|1] "" XXX
 SG_ RS_Verbau : 29|1@1+ (1.0,0.0) [0.0|1] "" XXX
 SG_ RS_Verglasung_schliessen : 30|1@1+ (1.0,0.0) [0.0|1] "" XXX
 SG_ RS_defekt : 31|1@1+ (1.0,0.0) [0.0|1] "" XXX
 SG_ RS_Wischergeschwindigkeit : 32|3@1+ (1.0,0.0) [0.0|7] "" XXX
 SG_ RLS_Vorfeldhelligkeit_Boost : 35|4@1+ (1.0,0.0) [0.0|15] "" XXX

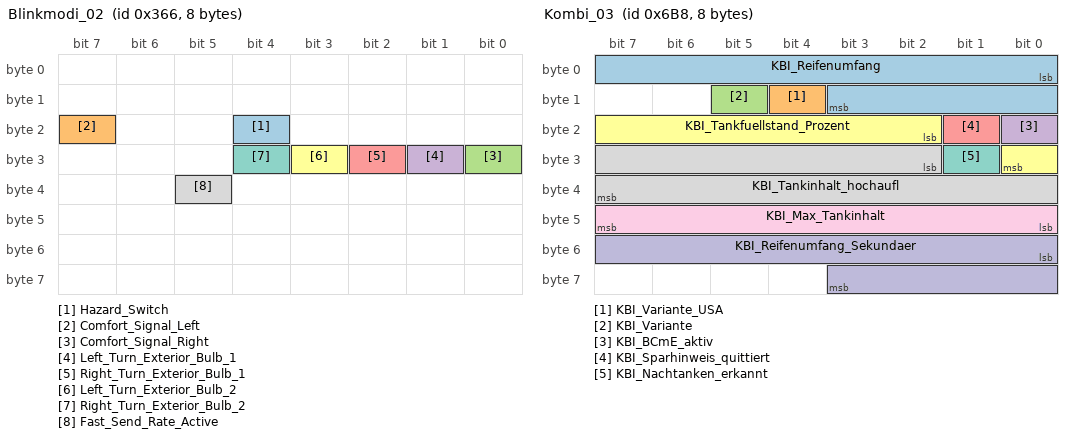
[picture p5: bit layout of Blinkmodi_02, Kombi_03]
BO_ 870 Blinkmodi_02: 8 XXX
 SG_ Hazard_Switch : 20|1@1+ (1,0) [0|1] ""  XXX
 SG_ Comfort_Signal_Left : 23|1@1+ (1,0) [0|1] ""  XXX
 SG_ Comfort_Signal_Right : 24|1@1+ (1,0) [0|1] ""  XXX
 SG_ Left_Turn_Exterior_Bulb_1 : 25|1@1+ (1,0) [0|1] ""  XXX
 SG_ Right_Turn_Exterior_Bulb_1 : 26|1@1+ (1,0) [0|1] ""  XXX
 SG_ Left_Turn_Exterior_Bulb_2 : 27|1@1+ (1,0) [0|1] ""  XXX
 SG_ Right_Turn_Exterior_Bulb_2 : 28|1@1+ (1,0) [0|1] ""  XXX
 SG_ Fast_Send_Rate_Active : 37|1@1+ (1,0) [0|1] ""  XXX

BO_ 1385 HVEM_04: 8 XXX

BO_ 1605 FLA_01: 8 XXX

BO_ 1624 Licht_vorne_01: 8 XXX
 SG_ LV_Standlicht_Anzeige : 12|1@1+ (1.0,0.0) [0.0|1] "" XXX
 SG_ LV_Abblendlicht_Anzeige : 13|1@1+ (1.0,0.0) [0.0|1] "" XXX
 SG_ LV_Fernlicht_Anzeige : 14|1@1+ (1.0,0.0) [0.0|1] "" XXX
 SG_ LV_Nebellicht_Anzeige : 15|1@1+ (1.0,0.0) [0.0|1] "" XXX
 SG_ LV_Nebelschlusslicht_Anzeige : 16|1@1+ (1.0,0.0) [0.0|1] "" XXX
 SG_ LV_Tagfahrlicht_Anzeige : 17|1@1+ (1.0,0.0) [0.0|1] "" XXX
 SG_ LV_AFL_aktiv_Anzeige : 18|1@1+ (1.0,0.0) [0.0|1] "" XXX
 SG_ LV_AFL_defekt : 19|1@1+ (1.0,0.0) [0.0|1] "" XXX
 SG_ LV_Blinker_li_def : 20|1@1+ (1.0,0.0) [0.0|1] "" XXX
 SG_ LV_Standlicht_li_def : 21|1@1+ (1.0,0.0) [0.0|1] "" XXX
 SG_ LV_Abblendlicht_li_def : 22|1@1+ (1.0,0.0) [0.0|1] "" XXX
 SG_ LV_Fernlicht_li_def : 23|1@1+ (1.0,0.0) [0.0|1] "" XXX
 SG_ LV_Nebellicht_li_def : 24|1@1+ (1.0,0.0) [0.0|1] "" XXX
 SG_ LV_Blk_li_Seite_def : 25|1@1+ (1.0,0.0) [0.0|1] "" XXX
 SG_ LV_Tagfahrlicht_li_def : 26|1@1+ (1.0,0.0) [0.0|1] "" XXX
 SG_ LV_FLA_aktiv_Anzeige : 27|1@1+ (1.0,0.0) [0.0|1] "" XXX
 SG_ LV_FLA_defekt : 28|1@1+ (1.0,0.0) [0.0|1] "" XXX
 SG_ LV_FLA_Sensor_blockiert : 29|1@1+ (1.0,0.0) [0.0|1] "" XXX
 SG_ LV_Blinker_re_def : 30|1@1+ (1.0,0.0) [0.0|1] "" XXX
 SG_ LV_Standlicht_re_def : 31|1@1+ (1.0,0.0) [0.0|1] "" XXX
 SG_ LV_Abblendlicht_re_def : 32|1@1+ (1.0,0.0) [0.0|1] "" XXX
 SG_ LV_Fernlicht_re_def : 33|1@1+ (1.0,0.0) [0.0|1] "" XXX
 SG_ LV_Nebellicht_re_def : 34|1@1+ (1.0,0.0) [0.0|1] "" XXX
 SG_ LV_Blk_re_Seite_def : 35|1@1+ (1.0,0.0) [0.0|1] "" XXX
 SG_ LV_Tagfahrlicht_re_def : 36|1@1+ (1.0,0.0) [0.0|1] "" XXX
 SG_ LV_Aussenlicht_def : 37|1@1+ (1.0,0.0) [0.0|1] "" XXX
 SG_ LV_Abblendlicht_TFL_li_def : 38|1@1+ (1.0,0.0) [0.0|1] "" XXX
 SG_ LV_Nebellicht_TFL_li_def : 39|1@1+ (1.0,0.0) [0.0|1] "" XXX
 SG_ LV_Standlicht_TFL_li_def : 40|1@1+ (1.0,0.0) [0.0|1] "" XXX
 SG_ LV_Abblend_Fernlicht_li_def : 41|1@1+ (1.0,0.0) [0.0|1] "" XXX
 SG_ LV_Abblendlicht_TFL_re_def : 42|1@1+ (1.0,0.0) [0.0|1] "" XXX
 SG_ LV_Nebellicht_TFL_re_def : 43|1@1+ (1.0,0.0) [0.0|1] "" XXX
 SG_ LV_Standlicht_TFL_re_def : 44|1@1+ (1.0,0.0) [0.0|1] "" XXX
 SG_ LV_Abblend_Fernlicht_re_def : 45|1@1+ (1.0,0.0) [0.0|1] "" XXX
 SG_ LV_Abbiegelicht_li_def : 46|1@1+ (1.0,0.0) [0.0|1] "" XXX
 SG_ LV_Abbiegelicht_re_def : 47|1@1+ (1.0,0.0) [0.0|1] "" XXX
 SG_ BCM1_Linksverkehr : 48|1@1+ (1.0,0.0) [0.0|1] "" XXX
 SG_ BCM1_Licht_Dunkelheit_aktiv : 49|1@1+ (1.0,0.0) [0.0|1] "" XXX
 SG_ LV_LED_Scheinwerfer_li_def : 50|1@1+ (1.0,0.0) [0.0|1] "" XXX
 SG_ LV_LED_Scheinwerfer_re_def : 51|1@1+ (1.0,0.0) [0.0|1] "" XXX
 SG_ LV_Blinker_VL_aktiv : 52|1@1+ (1.0,0.0) [0.0|1] "" XXX
 SG_ LV_Blinker_VR_aktiv : 53|1@1+ (1.0,0.0) [0.0|1] "" XXX
 SG_ LV_MXB_Status_Anzeige : 54|2@1+ (1.0,0.0) [0.0|3] "" XXX

BO_ 1646 Klima_03: 8 XXX
 SG_ KL_Geblaese_Status : 18|4@1+ (1.0,0.0) [0.0|15] "" XXX
 SG_ KL_Innen_Temp : 32|8@1+ (0.5,-50) [-50.0|76.0] "Unit_DegreCelsi" XXX

BO_ 1720 Kombi_03: 8 XXX
 SG_ KBI_Reifenumfang : 0|12@1+ (1,0) [0|4095] "Unit_MilliMeter"  XXX
 SG_ KBI_Variante_USA : 12|1@1+ (1.0,0.0) [0.0|1] ""  XXX
 SG_ KBI_Variante : 13|1@1+ (1.0,0.0) [0.0|1] ""  XXX
 SG_ KBI_BCmE_aktiv : 16|1@1+ (1.0,0.0) [0.0|1] ""  XXX
 SG_ KBI_Sparhinweis_quittiert : 17|1@1+ (1.0,0.0) [0.0|1] ""  XXX
 SG_ KBI_Tankfuellstand_Prozent : 18|7@1+ (1,0) [0|100] "Unit_PerCent"  XXX
 SG_ KBI_Nachtanken_erkannt : 25|1@1+ (1.0,0.0) [0.0|1] ""  XXX
 SG_ KBI_Tankinhalt_hochaufl : 26|14@1+ (0.01,0) [0.00|163.81] "Unit_Liter"  XXX
 SG_ KBI_Max_Tankinhalt : 40|8@1+ (0.5,0) [0.0|126.5] ""  XXX
 SG_ KBI_Reifenumfang_Sekundaer : 48|12@1+ (1,0) [0|4095] "Unit_MilliMeter"  XXX

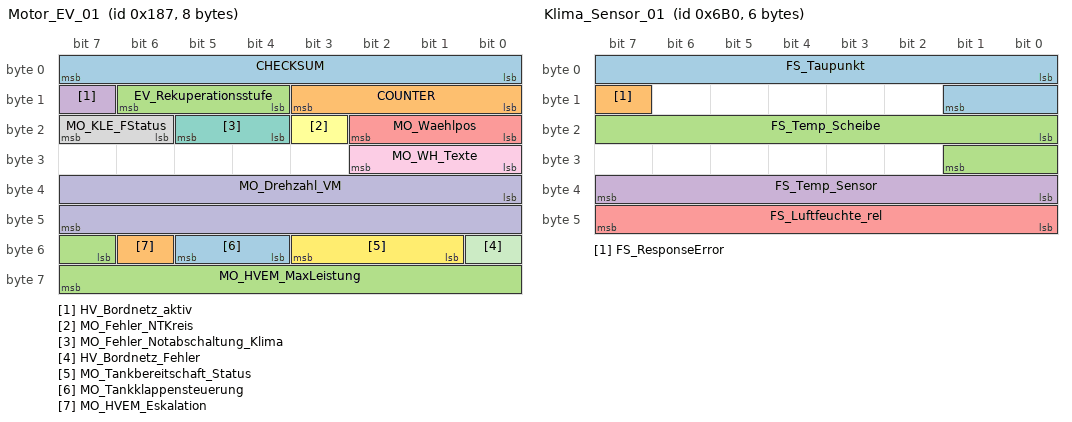
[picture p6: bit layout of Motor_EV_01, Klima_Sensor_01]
BO_ 391 Motor_EV_01: 8 Motor_MQB_BEV
 SG_ CHECKSUM : 0|8@1+ (1,0) [0|255] ""  XXX
 SG_ COUNTER : 8|4@1+ (1,0) [0|15] ""  XXX
 SG_ EV_Rekuperationsstufe : 12|3@1+ (1.0,0.0) [0.0|7] ""  XXX
 SG_ HV_Bordnetz_aktiv : 15|1@1+ (1.0,0.0) [0.0|1] ""  XXX
 SG_ MO_Waehlpos : 16|3@1+ (1.0,0.0) [0.0|7] ""  XXX
 SG_ MO_Fehler_NTKreis : 19|1@1+ (1.0,0.0) [0.0|1] ""  XXX
 SG_ MO_Fehler_Notabschaltung_Klima : 20|2@1+ (1.0,0.0) [0.0|3] ""  XXX
 SG_ MO_KLE_FStatus : 22|2@1+ (1.0,0.0) [0.0|3] ""  XXX
 SG_ MO_WH_Texte : 24|3@1+ (1.0,0.0) [0.0|7] ""  XXX
 SG_ MO_Drehzahl_VM : 32|16@1+ (0.25,0) [0.00|16383.00] "Unit_MinutInver"  XXX
 SG_ HV_Bordnetz_Fehler : 48|1@1+ (1.0,0.0) [0.0|1] ""  XXX
 SG_ MO_Tankbereitschaft_Status : 49|3@1+ (1.0,0.0) [0.0|7] ""  XXX
 SG_ MO_Tankklappensteuerung : 52|2@1+ (1.0,0.0) [0.0|3] ""  XXX
 SG_ MO_HVEM_Eskalation : 54|1@1+ (1.0,0.0) [0.0|1] ""  XXX
 SG_ MO_HVEM_MaxLeistung : 55|9@1+ (50,0) [0|25450] "Unit_Watt"  XXX

BO_ 980 SMLS_01: 8 XXX
 SG_ SMLS_01_CRC : 0|8@1+ (1,0) [0|255] "" XXX
 SG_ SMLS_01_BZ : 8|4@1+ (1,0) [0|15] "" XXX
 SG_ BH_Blinker_li : 12|1@1+ (1.0,0.0) [0.0|1] "" XXX
 SG_ BH_Blinker_re : 13|1@1+ (1.0,0.0) [0.0|1] "" XXX
 SG_ BH_Lichthupe : 14|1@1+ (1.0,0.0) [0.0|1] "" XXX
 SG_ BH_Fernlicht : 15|1@1+ (1.0,0.0) [0.0|1] "" XXX
 SG_ WH_Tipwischen : 16|1@1+ (1.0,0.0) [0.0|1] "" XXX
 SG_ WH_Intervall : 17|1@1+ (1.0,0.0) [0.0|1] "" XXX
 SG_ WH_WischerStufe1 : 18|1@1+ (1.0,0.0) [0.0|1] "" XXX
 SG_ WH_WischerStufe2 : 19|1@1+ (1.0,0.0) [0.0|1] "" XXX
 SG_ WH_Frontwaschen : 20|1@1+ (1.0,0.0) [0.0|1] "" XXX
 SG_ WH_Heckintervall : 21|1@1+ (1.0,0.0) [0.0|1] "" XXX
 SG_ WH_Heckwaschen : 22|1@1+ (1.0,0.0) [0.0|1] "" XXX
 SG_ WH_Intervallstufen : 23|4@1+ (1.0,0.0) [0.0|15] "" XXX
 SG_ FAS_Taster : 27|1@1+ (1.0,0.0) [0.0|1] "" XXX
 SG_ FAS_Taster_Fehler : 28|1@1+ (1.0,0.0) [0.0|1] "" XXX
 SG_ SMLS_Hupe : 29|1@1+ (1.0,0.0) [0.0|1] "" XXX
 SG_ LRH_On_Off : 30|2@1+ (1.0,0.0) [0.0|3] "" XXX
 SG_ LSS_Tastencode : 32|8@1+ (1.0,0.0) [0.0|255] "" XXX
 SG_ LRH_aktiv : 40|1@1+ (1.0,0.0) [0.0|1] "" XXX
 SG_ SMLS_P_verriegelt : 41|2@1+ (1.0,0.0) [0.0|3] "" XXX
 SG_ SMLS_P_verriegelt_plausibel : 43|1@1+ (1.0,0.0) [0.0|1] "" XXX
 SG_ WH_SRA : 44|1@1+ (1.0,0.0) [0.0|1] "" XXX
 SG_ WH_Wischer_Fehler : 45|1@1+ (1.0,0.0) [0.0|1] "" XXX
 SG_ BH_Blinker_Fehler : 46|1@1+ (1.0,0.0) [0.0|1] "" XXX
 SG_ SMLS_PTT : 47|1@1+ (1.0,0.0) [0.0|1] "" XXX
 SG_ WH_Tipwischen_lang : 48|1@1+ (1.0,0.0) [0.0|1] "" XXX

BO_ 1712 Klima_Sensor_01: 6 XXX
 SG_ FS_Taupunkt : 0|10@1+ (0.1,-39.6) [-39.5|60.4] "Unit_DegreCelsi" XXX
 SG_ FS_ResponseError : 15|1@1+ (1.0,0.0) [0.0|1] "" XXX
 SG_ FS_Temp_Scheibe : 16|10@1+ (0.1,-39.6) [-39.5|60.4] "Unit_DegreCelsi" XXX
 SG_ FS_Temp_Sensor : 32|8@1+ (0.5,-40) [-39.5|87.0] "Unit_DegreCelsi" XXX
 SG_ FS_Luftfeuchte_rel : 40|8@1+ (0.5,-0.5) [0.0|100.0] "Unit_PerCent" XXX

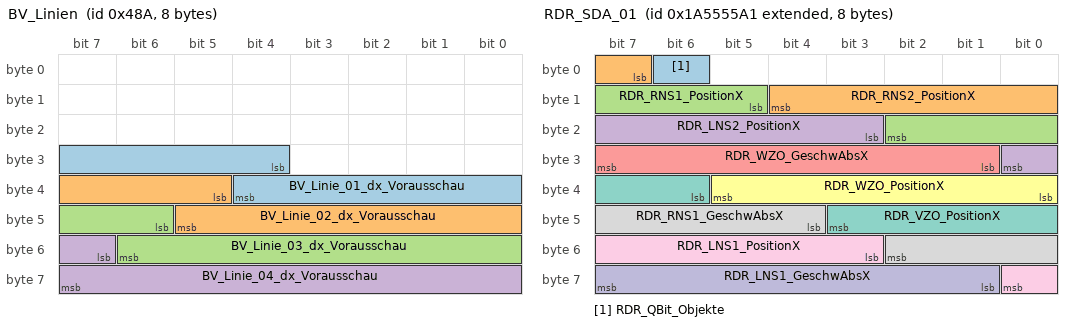
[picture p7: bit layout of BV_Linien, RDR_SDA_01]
BO_ 1162 BV_Linien: 8 XXX
 SG_ BV_Linie_01_dx_Vorausschau : 28|9@1+ (0.25,0) [0.00|127.75] "Unit_Meter" XXX
 SG_ BV_Linie_02_dx_Vorausschau : 37|9@1+ (0.25,0) [0.00|127.75] "Unit_Meter" XXX
 SG_ BV_Linie_03_dx_Vorausschau : 46|9@1+ (0.25,0) [0.00|127.75] "Unit_Meter" XXX
 SG_ BV_Linie_04_dx_Vorausschau : 55|9@1+ (0.25,0) [0.00|127.75] "Unit_Meter" XXX

BO_ 2589283745 RDR_SDA_01: 8 XXX
 SG_ RDR_QBit_Objekte : 6|1@1+ (1.0,0.0) [0.0|1] "" XXX
 SG_ RDR_RNS2_PositionX : 7|6@1+ (4.0323,0) [0.0000|250.0026] "Unit_Meter" XXX
 SG_ RDR_RNS1_PositionX : 13|6@1+ (4.0323,0) [0.0000|250.0026] "Unit_Meter" XXX
 SG_ RDR_LNS2_PositionX : 19|6@1+ (4.0323,0) [0.0000|250.0026] "Unit_Meter" XXX
 SG_ RDR_WZO_GeschwAbsX : 25|7@1+ (3.7874,-240) [-240.0000|237.2124] "Unit_KiloMeterPerHour" XXX
 SG_ RDR_WZO_PositionX : 32|6@1+ (4.0323,0) [0.0000|250.0026] "Unit_Meter" XXX
 SG_ RDR_VZO_PositionX : 38|6@1+ (4.0323,0) [0.0000|250.0026] "Unit_Meter" XXX
 SG_ RDR_RNS1_GeschwAbsX : 44|7@1+ (3.7874,-240) [-240.0000|237.2124] "Unit_KiloMeterPerHour" XXX
 SG_ RDR_LNS1_PositionX : 51|6@1+ (4.0323,0) [0.0000|250.0026] "Unit_Meter" XXX
 SG_ RDR_LNS1_GeschwAbsX : 57|7@1+ (3.7874,-240) [-240.0000|237.2124] "Unit_KiloMeterPerHour" XXX

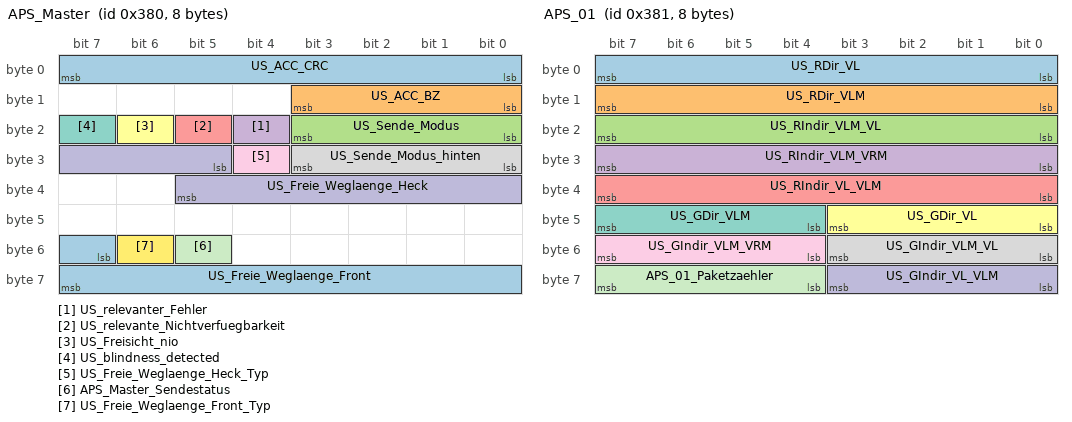
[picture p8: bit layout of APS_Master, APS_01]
BO_ 896 APS_Master: 8 XXX
 SG_ US_ACC_CRC : 0|8@1+ (1,0) [0|255] "" XXX
 SG_ US_ACC_BZ : 8|4@1+ (1,0) [0|15] "" XXX
 SG_ US_Sende_Modus : 16|4@1+ (1.0,0.0) [0.0|15] "" XXX
 SG_ US_relevanter_Fehler : 20|1@1+ (1.0,0.0) [0.0|1] "" XXX
 SG_ US_relevante_Nichtverfuegbarkeit : 21|1@1+ (1.0,0.0) [0.0|1] "" XXX
 SG_ US_Freisicht_nio : 22|1@1+ (1.0,0.0) [0.0|1] "" XXX
 SG_ US_blindness_detected : 23|1@1+ (1.0,0.0) [0.0|1] "" XXX
 SG_ US_Sende_Modus_hinten : 24|4@1+ (1.0,0.0) [0.0|15] "" XXX
 SG_ US_Freie_Weglaenge_Heck_Typ : 28|1@1+ (1.0,0.0) [0.0|1] "" XXX
 SG_ US_Freie_Weglaenge_Heck : 29|9@1+ (0.01,0) [0.00|5.00] "Unit_Meter" XXX
 SG_ APS_Master_Sendestatus : 53|1@1+ (1.0,0.0) [0.0|1] "" XXX
 SG_ US_Freie_Weglaenge_Front_Typ : 54|1@1+ (1.0,0.0) [0.0|1] "" XXX
 SG_ US_Freie_Weglaenge_Front : 55|9@1+ (0.01,0) [0.00|5.00] "Unit_Meter" XXX

BO_ 897 APS_01: 8 XXX
 SG_ US_RDir_VL : 0|8@1+ (0.02,0) [0.00|5.10] "Unit_Meter" XXX
 SG_ US_RDir_VLM : 8|8@1+ (0.02,0) [0.00|5.10] "Unit_Meter" XXX
 SG_ US_RIndir_VLM_VL : 16|8@1+ (0.02,0) [0.00|5.10] "Unit_Meter" XXX
 SG_ US_RIndir_VLM_VRM : 24|8@1+ (0.02,0) [0.00|5.10] "Unit_Meter" XXX
 SG_ US_RIndir_VL_VLM : 32|8@1+ (0.02,0) [0.00|5.10] "Unit_Meter" XXX
 SG_ US_GDir_VL : 40|4@1+ (0.066,0) [0.000|0.990] "" XXX
 SG_ US_GDir_VLM : 44|4@1+ (0.066,0) [0.000|0.990] "" XXX
 SG_ US_GIndir_VLM_VL : 48|4@1+ (0.066,0) [0.000|0.990] "" XXX
 SG_ US_GIndir_VLM_VRM : 52|4@1+ (0.066,0) [0.000|0.990] "" XXX
 SG_ US_GIndir_VL_VLM : 56|4@1+ (0.066,0) [0.000|0.990] "" XXX
 SG_ APS_01_Paketzaehler : 60|4@1+ (1,0) [0|15] "" XXX

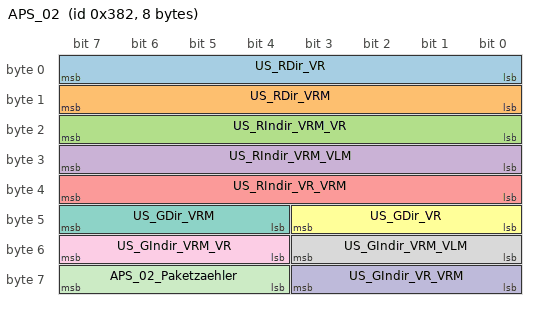
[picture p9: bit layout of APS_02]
BO_ 898 APS_02: 8 XXX
 SG_ US_RDir_VR : 0|8@1+ (0.02,0) [0.00|5.10] "Unit_Meter" XXX
 SG_ US_RDir_VRM : 8|8@1+ (0.02,0) [0.00|5.10] "Unit_Meter" XXX
 SG_ US_RIndir_VRM_VR : 16|8@1+ (0.02,0) [0.00|5.10] "Unit_Meter" XXX
 SG_ US_RIndir_VRM_VLM : 24|8@1+ (0.02,0) [0.00|5.10] "Unit_Meter" XXX
 SG_ US_RIndir_VR_VRM : 32|8@1+ (0.02,0) [0.00|5.10] "Unit_Meter" XXX
 SG_ US_GDir_VR : 40|4@1+ (0.066,0) [0.000|0.990] "" XXX
 SG_ US_GDir_VRM : 44|4@1+ (0.066,0) [0.000|0.990] "" XXX
 SG_ US_GIndir_VRM_VLM : 48|4@1+ (0.066,0) [0.000|0.990] "" XXX
 SG_ US_GIndir_VRM_VR : 52|4@1+ (0.066,0) [0.000|0.990] "" XXX
 SG_ US_GIndir_VR_VRM : 56|4@1+ (0.066,0) [0.000|0.990] "" XXX
 SG_ APS_02_Paketzaehler : 60|4@1+ (1,0) [0|15] "" XXX

BO_ 1654 Motor_21: 8 XXX
 SG_ StSt_Koord_Wiederstart_Anz_09 : 0|1@1+ (1.0,0.0) [0.0|1] "" XXX
 SG_ StSt_Koord_Wiederstart_Anz_10 : 1|1@1+ (1.0,0.0) [0.0|1] "" XXX
 SG_ StSt_Koord_Wiederstart_Anz_11 : 2|1@1+ (1.0,0.0) [0.0|1] "" XXX
 SG_ MO_Wiederstart_Anz_01 : 12|1@1+ (1.0,0.0) [0.0|1] "" XXX
 SG_ MO_Wiederstart_Anz_02 : 13|1@1+ (1.0,0.0) [0.0|1] "" XXX
 SG_ MO_Wiederstart_Anz_03 : 14|1@1+ (1.0,0.0) [0.0|1] "" XXX
 SG_ MO_Wiederstart_Anz_Std : 15|1@1+ (1.0,0.0) [0.0|1] "" XXX
 SG_ MO_Stoppverbot_Anz_01 : 16|1@1+ (1.0,0.0) [0.0|1] "" XXX
 SG_ MO_Stoppverbot_Anz_02 : 17|1@1+ (1.0,0.0) [0.0|1] "" XXX
 SG_ MO_Stoppverbot_Anz_03 : 18|1@1+ (1.0,0.0) [0.0|1] "" XXX
 SG_ MO_Stoppverbot_Anz_04 : 19|1@1+ (1.0,0.0) [0.0|1] "" XXX
 SG_ MO_Stoppverbot_Anz_05 : 20|1@1+ (1.0,0.0) [0.0|1] "" XXX
 SG_ MO_Stoppverbot_Anz_06 : 21|1@1+ (1.0,0.0) [0.0|1] "" XXX
 SG_ MO_Stoppverbot_Anz_07 : 22|1@1+ (1.0,0.0) [0.0|1] "" XXX
 SG_ MO_Stoppverbot_Anz_08 : 23|1@1+ (1.0,0.0) [0.0|1] "" XXX
 SG_ MO_Stoppverbot_Anz_09 : 24|1@1+ (1.0,0.0) [0.0|1] "" XXX
 SG_ MO_Stoppverbot_Anz_10 : 25|1@1+ (1.0,0.0) [0.0|1] "" XXX
 SG_ MO_Stoppverbot_Anz_11 : 26|1@1+ (1.0,0.0) [0.0|1] "" XXX
 SG_ MO_Stoppverbot_Anz_Std : 27|1@1+ (1.0,0.0) [0.0|1] "" XXX
 SG_ StSt_Koord_Stoppverbot_Anz_20 : 28|1@1+ (1.0,0.0) [0.0|1] "" XXX
 SG_ StSt_Koord_Stoppverbot_Anz_21 : 29|1@1+ (1.0,0.0) [0.0|1] "" XXX
 SG_ StSt_Koord_Wiederstart_Anz_Std : 30|1@1+ (1.0,0.0) [0.0|1] "" XXX
 SG_ StSt_Koord_Status_Bremspedalkzpt : 31|1@1+ (1.0,0.0) [0.0|1] "" XXX
 SG_ StSt_Koord_Wiederstart_Anz_01 : 32|1@1+ (1.0,0.0) [0.0|1] "" XXX
 SG_ StSt_Koord_Wiederstart_Anz_02 : 33|1@1+ (1.0,0.0) [0.0|1] "" XXX
 SG_ StSt_Koord_Wiederstart_Anz_03 : 34|1@1+ (1.0,0.0) [0.0|1] "" XXX
 SG_ StSt_Koord_Wiederstart_Anz_04 : 35|1@1+ (1.0,0.0) [0.0|1] "" XXX
 SG_ StSt_Koord_Wiederstart_Anz_05 : 36|1@1+ (1.0,0.0) [0.0|1] "" XXX
 SG_ StSt_Koord_Wiederstart_Anz_06 : 37|1@1+ (1.0,0.0) [0.0|1] "" XXX
 SG_ StSt_Koord_Wiederstart_Anz_07 : 38|1@1+ (1.0,0.0) [0.0|1] "" XXX
 SG_ StSt_Koord_Wiederstart_Anz_08 : 39|1@1+ (1.0,0.0) [0.0|1] "" XXX
 SG_ StSt_Koord_Stoppverbot_Anz_01 : 40|1@1+ (1.0,0.0) [0.0|1] "" XXX
 SG_ StSt_Koord_Stoppverbot_Anz_02 : 41|1@1+ (1.0,0.0) [0.0|1] "" XXX
 SG_ StSt_Koord_Stoppverbot_Anz_03 : 42|1@1+ (1.0,0.0) [0.0|1] "" XXX
 SG_ StSt_Koord_Stoppverbot_Anz_04 : 43|1@1+ (1.0,0.0) [0.0|1] "" XXX
 SG_ StSt_Koord_Stoppverbot_Anz_05 : 44|1@1+ (1.0,0.0) [0.0|1] "" XXX
 SG_ StSt_Koord_Stoppverbot_Anz_06 : 45|1@1+ (1.0,0.0) [0.0|1] "" XXX
 SG_ StSt_Koord_Stoppverbot_Anz_07 : 46|1@1+ (1.0,0.0) [0.0|1] "" XXX
 SG_ StSt_Koord_Stoppverbot_Anz_08 : 47|1@1+ (1.0,0.0) [0.0|1] "" XXX
 SG_ StSt_Koord_Stoppverbot_Anz_09 : 48|1@1+ (1.0,0.0) [0.0|1] "" XXX
 SG_ StSt_Koord_Stoppverbot_Anz_10 : 49|1@1+ (1.0,0.0) [0.0|1] "" XXX
 SG_ StSt_Koord_Stoppverbot_Anz_11 : 50|1@1+ (1.0,0.0) [0.0|1] "" XXX
 SG_ StSt_Koord_Stoppverbot_Anz_12 : 51|1@1+ (1.0,0.0) [0.0|1] "" XXX
 SG_ StSt_Koord_Stoppverbot_Anz_13 : 52|1@1+ (1.0,0.0) [0.0|1] "" XXX
 SG_ StSt_Koord_Stoppverbot_Anz_14 : 53|1@1+ (1.0,0.0) [0.0|1] "" XXX
 SG_ StSt_Koord_Stoppverbot_Anz_15 : 54|1@1+ (1.0,0.0) [0.0|1] "" XXX
 SG_ StSt_Koord_Stoppverbot_Anz_16 : 55|1@1+ (1.0,0.0) [0.0|1] "" XXX
 SG_ StSt_Koord_Stoppverbot_Anz_17 : 56|1@1+ (1.0,0.0) [0.0|1] "" XXX
 SG_ StSt_Koord_Stoppverbot_Anz_Std : 57|1@1+ (1.0,0.0) [0.0|1] "" XXX
 SG_ StSt_Koord_Stoppverbot_Anz_18 : 58|1@1+ (1.0,0.0) [0.0|1] "" XXX
 SG_ StSt_Koord_Stoppverbot_Anz_19 : 59|1@1+ (1.0,0.0) [0.0|1] "" XXX
 SG_ MO_StaGluehk : 60|4@1+ (8,0) [0|112] "Unit_PerCent" XXX

CM_ SG_ 988 GE_Fahrstufe "Selector position. 2016 Golf Mk7 DQ200: D = 8, S = 9, D shown as E with the Eco drive profile = 10, tiptronic = 14 (same values as Getriebe_11).";
CM_ BO_ 1122 "Predictive route data (PSD, electronic horizon) from the navigation unit: road segments ahead. Layout from vw_meb (same VW PSD protocol); checked on a 2016 Golf Mk7 with Discover Media/Pro.";
CM_ BO_ 1123 "Predictive route data (PSD): vehicle position on the segment tree and segment attributes with offsets.";
CM_ BO_ 385 "Front camera traffic sign recognition (VZE), signs 1-3 as shown on the cluster. On a 2016 Golf Mk7 (AU, km/h) speed-limit signs read VZE_Verkehrszeichen_x * 5 = km/h (seen 40, 50, 60, 80, 100, 110).";
CM_ SG_ 385 VZE_Hinweistext "3 once a sign has been recognised, 0 before the first sign (2016 Golf Mk7, AU).";
CM_ SG_ 385 VZE_Verkehrszeichen_1 "Main sign, coded per VW hash table, 0 = none. Speed limits: value * 5 = km/h on a 2016 Golf Mk7 (AU).";
CM_ SG_ 385 VZE_Verkehrszeichen_2 "Second sign shown alongside the first (seen as 40 with a 50 main sign, e.g. a school zone). Same coding as VZE_Verkehrszeichen_1.";
CM_ SG_ 385 VZE_Warnung_Verkehrszeichen_1 "Set on every school-zone 40 sign on a 2016 Golf Mk7 (AU); treated as a conditional sign.";
CM_ SG_ 385 VZE_Zusatzschild_1 "Supplementary plate for sign 1, coded per VW hash table. Always 0 on a 2016 Golf Mk7 (AU), school zones included.";
CM_ SG_ 385 VZE_Zeichen_01_Kamera "Sign 1 comes from the camera.";
CM_ SG_ 385 VZE_Zeichen_01_Karte "Sign 1 comes from the map.";
CM_ SG_ 385 VZE_Zeichen_01_Gesetz "Sign 1 is the default legal limit.";
CM_ SG_ 385 VZE_Zeichen_01_KameraWied "Sign 1 was recognised by the camera as a repeater sign.";
CM_ BO_ 668 "Front camera traffic sign recognition (VZE), signs 4-5. Same coding as VZE_01.";
CM_ BO_ 806 "Front camera lane line model: own lane, left line. 12.5 Hz, no checksum/counter. Checked against openpilot modelV2 lane lines on a 2016 Golf Mk7. Lookahead distance for this line is BV_Linien.BV_Linie_01_dx_Vorausschau.";
CM_ SG_ 806 BV_Linie_01_dy "Lateral distance to the line, positive = left. r=0.95 vs model (own-lane lines).";
CM_ SG_ 806 BV_Linie_01_Gierw_diff "Line angle relative to the car, positive = pointing left. r=0.76 vs model (own-lane lines).";
CM_ SG_ 806 BV_Linie_01_hor_Kruemmung "Line curvature, positive = bending left. r=0.85 vs model; roughly 2e-5 1/m per step.";
CM_ SG_ 806 BV_Linie_01_hor_Kruemm_Aend "Curvature change along the line.";
CM_ SG_ 806 BV_Linie_01_Existenzmass "Line existence confidence, 0 when there is no line.";
CM_ BO_ 807 "Front camera lane line model: own lane, right line. 12.5 Hz, no checksum/counter. Checked against openpilot modelV2 lane lines on a 2016 Golf Mk7. Lookahead distance for this line is BV_Linien.BV_Linie_02_dx_Vorausschau.";
CM_ SG_ 807 BV_Linie_02_dy "Lateral distance to the line, positive = left. r=0.95 vs model (own-lane lines).";
CM_ SG_ 807 BV_Linie_02_Gierw_diff "Line angle relative to the car, positive = pointing left. r=0.76 vs model (own-lane lines).";
CM_ SG_ 807 BV_Linie_02_hor_Kruemmung "Line curvature, positive = bending left. r=0.85 vs model; roughly 2e-5 1/m per step.";
CM_ SG_ 807 BV_Linie_02_hor_Kruemm_Aend "Curvature change along the line.";
CM_ SG_ 807 BV_Linie_02_Existenzmass "Line existence confidence, 0 when there is no line.";
CM_ BO_ 808 "Front camera lane line model: next line out to the left. 12.5 Hz, no checksum/counter. Checked against openpilot modelV2 lane lines on a 2016 Golf Mk7. Lookahead distance for this line is BV_Linien.BV_Linie_03_dx_Vorausschau.";
CM_ SG_ 808 BV_Linie_03_dy "Lateral distance to the line, positive = left. r=0.95 vs model (own-lane lines).";
CM_ SG_ 808 BV_Linie_03_Gierw_diff "Line angle relative to the car, positive = pointing left. r=0.76 vs model (own-lane lines).";
CM_ SG_ 808 BV_Linie_03_hor_Kruemmung "Line curvature, positive = bending left. r=0.85 vs model; roughly 2e-5 1/m per step.";
CM_ SG_ 808 BV_Linie_03_hor_Kruemm_Aend "Curvature change along the line.";
CM_ SG_ 808 BV_Linie_03_Existenzmass "Line existence confidence, 0 when there is no line.";
CM_ BO_ 809 "Front camera lane line model: next line out to the right. 12.5 Hz, no checksum/counter. Checked against openpilot modelV2 lane lines on a 2016 Golf Mk7. Lookahead distance for this line is BV_Linien.BV_Linie_04_dx_Vorausschau.";
CM_ SG_ 809 BV_Linie_04_dy "Lateral distance to the line, positive = left. r=0.95 vs model (own-lane lines).";
CM_ SG_ 809 BV_Linie_04_Gierw_diff "Line angle relative to the car, positive = pointing left. r=0.76 vs model (own-lane lines).";
CM_ SG_ 809 BV_Linie_04_hor_Kruemmung "Line curvature, positive = bending left. r=0.85 vs model; roughly 2e-5 1/m per step.";
CM_ SG_ 809 BV_Linie_04_hor_Kruemm_Aend "Curvature change along the line.";
CM_ SG_ 809 BV_Linie_04_Existenzmass "Line existence confidence, 0 when there is no line.";
CM_ SG_ 1175 PH_StartStopp_Info "Stop enable and start request to the start/stop coordinator";
CM_ BO_ 2589283745 "Radar 'swarm data' view of nearby vehicles, about 1 Hz, 4 m / 3.8 km/h steps. On a 2016 Golf Mk7: WZO = the followed target (tracks openpilot's lead, read ~4 m long), VZO = the vehicle ahead of it, LNS1/2 and RNS1/2 = 1st/2nd vehicle in the left/right lane. 254 m = no vehicle.";
CM_ SG_ 2589283745 RDR_QBit_Objekte "(RDR_Qbit_Objekte) Set to error or substitute value when the radar ECU cannot detect objects reliably.";
CM_ SG_ 2589283745 RDR_RNS2_PositionX "Distance in x to the 2nd vehicle in the right lane";
CM_ SG_ 2589283745 RDR_RNS1_PositionX "Distance in x to the 1st vehicle in the right lane";
CM_ SG_ 2589283745 RDR_LNS2_PositionX "Distance in x to the 2nd vehicle in the left lane";
CM_ SG_ 2589283745 RDR_WZO_GeschwAbsX "Absolute speed of the vehicle ahead in the ego lane";
CM_ SG_ 2589283745 RDR_WZO_PositionX "Distance in x to the 1st vehicle in the ego lane";
CM_ SG_ 2589283745 RDR_VZO_PositionX "Distance in x to the 2nd vehicle in the ego lane";
CM_ SG_ 2589283745 RDR_RNS1_GeschwAbsX "Absolute speed of the 1st vehicle in the right lane";
CM_ SG_ 2589283745 RDR_LNS1_PositionX "Distance in x to the 1st vehicle in the left lane";
CM_ SG_ 2589283745 RDR_LNS1_GeschwAbsX "Absolute speed of the 1st vehicle in the left lane";
CM_ BO_ 896 "Ultrasonic park distance (parking sensors) master status. Present on a 2016 Golf Mk7 with front/rear parking sensors (no Park Assist).";
CM_ SG_ 896 US_ACC_CRC "From MQB and MLBevo: 'Calculation see specification End-to-End communication protection'. End values see accompanying document 'S-PDU identifier sequences'";
CM_ SG_ 896 US_Sende_Modus "US = ultrasonic. US_SendeModus: 0x0 no distance values relevant to the ACC ECU 0x1 4K ext. range, 10 signal paths ('4 m') 0x2 4K norm. range, 10 signal paths ('2 m') 0x3 6K ext. range, 16 signal paths ('4 m') ...";
CM_ SG_ 896 US_relevanter_Fehler "Ultrasonic detects a fault in front object detection, fault stored.";
CM_ SG_ 896 US_relevante_Nichtverfuegbarkeit "Ultrasonic detects unavailability of front object detection, no fault stored";
CM_ SG_ 896 US_Freisicht_nio "Blindness detection: clear-view check not yet passed since ignition on";
CM_ SG_ 896 US_blindness_detected "Ultrasonic detects its own blindness from external influences.";
CM_ SG_ 896 US_Sende_Modus_hinten "US = ultrasonic. US_Sende_Modus_hinten: 0x0 no distance values relevant to the ACC ECU 0x1-0x4 free 0x5 2K ext. range (PLA), 2 signal paths ('4 m') 0x6 mode switch (ext -> norm or norm -> ext) 0x7 blindness check ...";
CM_ SG_ 896 US_Freie_Weglaenge_Heck_Typ "US_Freie_Weglaenge_Typ says whether US_Freie_Weglaenge_Heck is a measured object or the maximum sensor range. Belongs to US_Freie_Weglaenge_Front";
CM_ SG_ 896 US_Freie_Weglaenge_Heck "Steering-angle-dependent distance behind the vehicle: either to an obstacle or the maximum visible range. See US_Freie_Weglaenge... to tell them apart.";
CM_ SG_ 896 APS_Master_Sendestatus "Transmit status of APS_Master (needed for IL support)";
CM_ SG_ 896 US_Freie_Weglaenge_Front_Typ "Limit of the free path ahead of the vehicle; belongs to US_Freie_Weglaenge_Front. The free path can end at a measured object or at the maximum sensor range.";
CM_ SG_ 896 US_Freie_Weglaenge_Front "Ultrasonic free path ahead of the vehicle, steering-angle dependent; limited by obstacles or the maximum visible range. See US_Freie_Weglaenge_Front_Typ";
CM_ BO_ 897 "Ultrasonic park distance, front left sensors: direct (Dir) and cross (Indir) echo distances and their quality (G...). 5.1 m = nothing in range.";
CM_ SG_ 897 US_RDir_VL "Direct measurement, ultrasonic sensor front left";
CM_ SG_ 897 US_RDir_VLM "Direct measurement, ultrasonic sensor front left-centre";
CM_ SG_ 897 US_RIndir_VLM_VL "Indirect measurement, ultrasonic sensors front left-centre (transmitter) and front left (receiver)";
CM_ SG_ 897 US_RIndir_VLM_VRM "Indirect measurement, ultrasonic sensors front left-centre (transmitter) and front right-centre (receiver)";
CM_ SG_ 897 US_RIndir_VL_VLM "Indirect measurement, ultrasonic sensors front left (transmitter) and front left-centre (receiver)";
CM_ SG_ 897 US_GDir_VL "Quality of the direct measurement, ultrasonic sensor front left";
CM_ SG_ 897 US_GDir_VLM "Quality of the direct measurement, ultrasonic sensor front left-centre";
CM_ SG_ 897 US_GIndir_VLM_VL "Quality of the indirect measurement, ultrasonic sensors front left-centre (transmitter) and front left (receiver)";
CM_ SG_ 897 US_GIndir_VLM_VRM "Quality of the indirect measurement, ultrasonic sensors front left-centre (transmitter) and front right-centre (receiver)";
CM_ SG_ 897 US_GIndir_VL_VLM "Quality of the indirect measurement, ultrasonic sensors front left (transmitter) and front left-centre (receiver)";
CM_ SG_ 897 APS_01_Paketzaehler "Used to verify message order APS_Master, APS_01, APS_02";
CM_ BO_ 898 "Ultrasonic park distance, front right sensors: direct (Dir) and cross (Indir) echo distances and their quality (G...). 5.1 m = nothing in range.";
CM_ SG_ 898 US_RDir_VR "Direct measurement, ultrasonic sensor front right";
CM_ SG_ 898 US_RDir_VRM "Direct measurement, ultrasonic sensor front right-centre";
CM_ SG_ 898 US_RIndir_VRM_VR "Indirect measurement, ultrasonic sensors front right-centre (transmitter) and front right (receiver)";
CM_ SG_ 898 US_RIndir_VRM_VLM "Indirect measurement, ultrasonic sensors front right-centre (transmitter) and front left-centre (receiver)";
CM_ SG_ 898 US_RIndir_VR_VRM "Indirect measurement, ultrasonic sensors front right (transmitter) and front right-centre (receiver)";
CM_ SG_ 898 US_GDir_VR "Quality of the direct measurement, ultrasonic sensor front right";
CM_ SG_ 898 US_GDir_VRM "Quality of the direct measurement, ultrasonic sensor front right-centre";
CM_ SG_ 898 US_GIndir_VRM_VLM "Quality of the indirect measurement, ultrasonic sensors front right-centre (transmitter) and front left-centre (receiver)";
CM_ SG_ 898 US_GIndir_VRM_VR "Quality of the indirect measurement, ultrasonic sensors front right-centre (transmitter) and front right (receiver)";
CM_ SG_ 898 US_GIndir_VR_VRM "Quality of the indirect measurement, ultrasonic sensors front right (transmitter) and front right-centre (receiver)";
CM_ SG_ 898 APS_02_Paketzaehler "Used to verify message order APS_Master, APS_01, APS_02";
CM_ BO_ 1654 "Start/Stop coordinator status: why the engine may not stop (Stoppverbot) or must restart (Wiederstart). Powertrain CAN (gateway harness bus 1).";
CM_ SG_ 1654 StSt_Koord_Wiederstart_Anz_09 "Detailed reason for a restart request from the start/stop coordinator.";
CM_ SG_ 1654 StSt_Koord_Wiederstart_Anz_10 "Detailed reason for a restart request from the start/stop coordinator.";
CM_ SG_ 1654 StSt_Koord_Wiederstart_Anz_11 "Detailed reason for a restart request from the start/stop coordinator.";
CM_ SG_ 1654 MO_Wiederstart_Anz_01 "Detailed reason for a restart request from the engine.";
CM_ SG_ 1654 MO_Wiederstart_Anz_02 "Detailed reason for a restart request from the engine.";
CM_ SG_ 1654 MO_Wiederstart_Anz_03 "Detailed reason for a restart request from the engine.";
CM_ SG_ 1654 MO_Wiederstart_Anz_Std "Detailed reason for a restart request from the engine.";
CM_ SG_ 1654 MO_Stoppverbot_Anz_01 "Detailed reason for an engine stop prohibition from the engine.";
CM_ SG_ 1654 MO_Stoppverbot_Anz_02 "Detailed reason for an engine stop prohibition from the engine.";
CM_ SG_ 1654 MO_Stoppverbot_Anz_03 "Detailed reason for an engine stop prohibition from the engine.";
CM_ SG_ 1654 MO_Stoppverbot_Anz_04 "Detailed reason for an engine stop prohibition from the engine.";
CM_ SG_ 1654 MO_Stoppverbot_Anz_05 "Detailed reason for an engine stop prohibition from the engine.";
CM_ SG_ 1654 MO_Stoppverbot_Anz_06 "Detailed reason for an engine stop prohibition from the engine.";
CM_ SG_ 1654 MO_Stoppverbot_Anz_07 "Detailed reason for an engine stop prohibition from the engine.";
CM_ SG_ 1654 MO_Stoppverbot_Anz_08 "Detailed reason for an engine stop prohibition from the engine.";
CM_ SG_ 1654 MO_Stoppverbot_Anz_09 "Detailed reason for an engine stop prohibition from the engine.";
CM_ SG_ 1654 MO_Stoppverbot_Anz_10 "Detailed reason for an engine stop prohibition from the engine.";
CM_ SG_ 1654 MO_Stoppverbot_Anz_11 "Detailed reason for an engine stop prohibition from the engine.";
CM_ SG_ 1654 MO_Stoppverbot_Anz_Std "Detailed reason for an engine stop prohibition from the engine.";
CM_ SG_ 1654 StSt_Koord_Stoppverbot_Anz_20 "Engine must keep running because of online traffic-light info. 0 = engine stop not prevented by traffic-light info, 1 = traffic-light info prevents engine stop";
CM_ SG_ 1654 StSt_Koord_Stoppverbot_Anz_21 "Engine must keep running because of race mode, S or tiptronic. 0 = not prevented, 1 = race mode, S or tiptronic prevents engine stop";
CM_ SG_ 1654 StSt_Koord_Wiederstart_Anz_Std "Detailed reason for a restart request from the start/stop coordinator.";
CM_ SG_ 1654 StSt_Koord_Status_Bremspedalkzpt "Whether the brake pedal concept (start request, automatic) is active.";
CM_ SG_ 1654 StSt_Koord_Wiederstart_Anz_01 "Detailed reason for a restart request from the start/stop coordinator.";
CM_ SG_ 1654 StSt_Koord_Wiederstart_Anz_02 "Detailed reason for a restart request from the start/stop coordinator.";
CM_ SG_ 1654 StSt_Koord_Wiederstart_Anz_03 "Detailed reason for a restart request from the start/stop coordinator.";
CM_ SG_ 1654 StSt_Koord_Wiederstart_Anz_04 "Detailed reason for a restart request from the start/stop coordinator.";
CM_ SG_ 1654 StSt_Koord_Wiederstart_Anz_05 "Detailed reason for a restart request from the start/stop coordinator.";
CM_ SG_ 1654 StSt_Koord_Wiederstart_Anz_06 "Detailed reason for a restart request from the start/stop coordinator.";
CM_ SG_ 1654 StSt_Koord_Wiederstart_Anz_07 "Detailed reason for a restart request from the start/stop coordinator.";
CM_ SG_ 1654 StSt_Koord_Wiederstart_Anz_08 "Detailed reason for a restart request from the start/stop coordinator.";
CM_ SG_ 1654 StSt_Koord_Stoppverbot_Anz_01 "Detailed reason for an engine stop prohibition from the start/stop coordinator.";
CM_ SG_ 1654 StSt_Koord_Stoppverbot_Anz_02 "Detailed reason for an engine stop prohibition from the start/stop coordinator.";
CM_ SG_ 1654 StSt_Koord_Stoppverbot_Anz_03 "Detailed reason for an engine stop prohibition from the start/stop coordinator.";
CM_ SG_ 1654 StSt_Koord_Stoppverbot_Anz_04 "Detailed reason for an engine stop prohibition from the start/stop coordinator.";
CM_ SG_ 1654 StSt_Koord_Stoppverbot_Anz_05 "Detailed reason for an engine stop prohibition from the start/stop coordinator.";
CM_ SG_ 1654 StSt_Koord_Stoppverbot_Anz_06 "Detailed reason for an engine stop prohibition from the start/stop coordinator.";
CM_ SG_ 1654 StSt_Koord_Stoppverbot_Anz_07 "Detailed reason for an engine stop prohibition from the start/stop coordinator.";
CM_ SG_ 1654 StSt_Koord_Stoppverbot_Anz_08 "Detailed reason for an engine stop prohibition from the start/stop coordinator.";
CM_ SG_ 1654 StSt_Koord_Stoppverbot_Anz_09 "Detailed reason for an engine stop prohibition from the start/stop coordinator.";
CM_ SG_ 1654 StSt_Koord_Stoppverbot_Anz_10 "Detailed reason for an engine stop prohibition from the start/stop coordinator.";
CM_ SG_ 1654 StSt_Koord_Stoppverbot_Anz_11 "Detailed reason for an engine stop prohibition from the start/stop coordinator.";
CM_ SG_ 1654 StSt_Koord_Stoppverbot_Anz_12 "Detailed reason for an engine stop prohibition from the start/stop coordinator.";
CM_ SG_ 1654 StSt_Koord_Stoppverbot_Anz_13 "Detailed reason for an engine stop prohibition from the start/stop coordinator.";
CM_ SG_ 1654 StSt_Koord_Stoppverbot_Anz_14 "Detailed reason for an engine stop prohibition from the start/stop coordinator.";
CM_ SG_ 1654 StSt_Koord_Stoppverbot_Anz_15 "Detailed reason for an engine stop prohibition from the start/stop coordinator.";
CM_ SG_ 1654 StSt_Koord_Stoppverbot_Anz_16 "Detailed reason for an engine stop prohibition from the start/stop coordinator.";
CM_ SG_ 1654 StSt_Koord_Stoppverbot_Anz_17 "Whether a further driver action (e.g. releasing the clutch) is needed for an engine stop. 0 = engine stop not prevented by driver action, 1 = missing driver action prevents engine stop";
CM_ SG_ 1654 StSt_Koord_Stoppverbot_Anz_Std "Detailed reason for an engine stop prohibition from the start/stop coordinator.";
CM_ SG_ 1654 StSt_Koord_Stoppverbot_Anz_18 "Engine must keep running because of PSD (predictive route data). 0 = engine stop not prevented by PSD, 1 = PSD prevents engine stop";
CM_ SG_ 1654 StSt_Koord_Stoppverbot_Anz_19 "Engine must keep running because of short-stop detection. 0 = engine stop not prevented by short-stop detection, 1 = short-stop detection prevents engine stop";
CM_ SG_ 1654 MO_StaGluehk "Glow plug heating duty in percent";
CM_ BO_ 980 "Steering column switch module (stalks). On the powertrain CAN (gateway harness bus 1), sent about once a second and on change. BH_Blinker_li/re match carState blinkers on a 2016 Golf Mk7 (AU).";
CM_ SG_ 980 WH_Intervall "Wiper stalk in intermittent position. Seen toggling on a 2016 Golf Mk7 (AU); not yet checked against rain.";
CM_ SG_ 980 WH_WischerStufe2 "Wiper stalk in fast position. Seen toggling on a 2016 Golf Mk7 (AU); not yet checked against rain.";
CM_ BO_ 1712 "Windscreen humidity/temperature sensor (behind the mirror). On a 2016 Golf Mk7 (AU): humidity 45-65 %, dew point 8-12 C, glass 15-23 C.";
CM_ SG_ 1712 FS_Taupunkt "Dew point.";
CM_ SG_ 1712 FS_Temp_Scheibe "Windscreen glass temperature. Glass at or below FS_Taupunkt means the screen can mist up.";
CM_ SG_ 1712 FS_Luftfeuchte_rel "Relative humidity at the windscreen.";
CM_ BO_ 1162 "How far ahead the camera sees each lane line (BV_Linie_01..04 = own lane left, own lane right, next line out left, next line out right). 0 when the line is not seen; up to 100 m on a 2016 Golf Mk7 (AU).";
CM_ SG_ 1123 PSD_Attribut_1_ID "Attribute type. Seen on a 2016 Golf Mk7 (AU), checked against OpenStreetMap on 47 drives: 3 = roundabout (value 1 at the entry, 93% within 35 m of a mapped roundabout; 0 at the exit, 84%), 10 = right of way at the junction ahead (value 8 = roundabout, 93%; 1 and 2 unconfirmed), 11 = traffic lights (value 1, 62% at mapped signals, 71% at signalised crossings), 14 = also at traffic lights (value 1, 84%; exact meaning unclear); 4 is likely carriageway separation (1 on freeways and main roads, 2 on undivided country and district roads); 2 is likely a road class rank (5 freeway/main, 2 main/country, 1 country/district, 0 local/unpaved); 6 and 15 are freeway road properties (6 = 0 seen on ramps); 7, 17 and others are not identified yet.";
CM_ SG_ 1123 PSD_Attribut_2_ID "Attribute type. Seen on a 2016 Golf Mk7 (AU), checked against OpenStreetMap on 47 drives: 3 = roundabout (value 1 at the entry, 93% within 35 m of a mapped roundabout; 0 at the exit, 84%), 10 = right of way at the junction ahead (value 8 = roundabout, 93%; 1 and 2 unconfirmed), 11 = traffic lights (value 1, 62% at mapped signals, 71% at signalised crossings), 14 = also at traffic lights (value 1, 84%; exact meaning unclear); 4 is likely carriageway separation (1 on freeways and main roads, 2 on undivided country and district roads); 2 is likely a road class rank (5 freeway/main, 2 main/country, 1 country/district, 0 local/unpaved); 6 and 15 are freeway road properties (6 = 0 seen on ramps); 7, 17 and others are not identified yet.";
CM_ SG_ 1124 PSD_Attribut_3_ID "Attribute type. Seen on a 2016 Golf Mk7 (AU), checked against OpenStreetMap on 47 drives: 3 = roundabout (value 1 at the entry, 93% within 35 m of a mapped roundabout; 0 at the exit, 84%), 10 = right of way at the junction ahead (value 8 = roundabout, 93%; 1 and 2 unconfirmed), 11 = traffic lights (value 1, 62% at mapped signals, 71% at signalised crossings), 14 = also at traffic lights (value 1, 84%; exact meaning unclear); 4 is likely carriageway separation (1 on freeways and main roads, 2 on undivided country and district roads); 2 is likely a road class rank (5 freeway/main, 2 main/country, 1 country/district, 0 local/unpaved); 6 and 15 are freeway road properties (6 = 0 seen on ramps); 7, 17 and others are not identified yet.";
CM_ SG_ 1124 PSD_Attribut_4_ID "Attribute type. Seen on a 2016 Golf Mk7 (AU), checked against OpenStreetMap on 47 drives: 3 = roundabout (value 1 at the entry, 93% within 35 m of a mapped roundabout; 0 at the exit, 84%), 10 = right of way at the junction ahead (value 8 = roundabout, 93%; 1 and 2 unconfirmed), 11 = traffic lights (value 1, 62% at mapped signals, 71% at signalised crossings), 14 = also at traffic lights (value 1, 84%; exact meaning unclear); 4 is likely carriageway separation (1 on freeways and main roads, 2 on undivided country and district roads); 2 is likely a road class rank (5 freeway/main, 2 main/country, 1 country/district, 0 local/unpaved); 6 and 15 are freeway road properties (6 = 0 seen on ramps); 7, 17 and others are not identified yet.";
CM_ SG_ 1124 PSD_Attribut_5_ID "Attribute type. Seen on a 2016 Golf Mk7 (AU), checked against OpenStreetMap on 47 drives: 3 = roundabout (value 1 at the entry, 93% within 35 m of a mapped roundabout; 0 at the exit, 84%), 10 = right of way at the junction ahead (value 8 = roundabout, 93%; 1 and 2 unconfirmed), 11 = traffic lights (value 1, 62% at mapped signals, 71% at signalised crossings), 14 = also at traffic lights (value 1, 84%; exact meaning unclear); 4 is likely carriageway separation (1 on freeways and main roads, 2 on undivided country and district roads); 2 is likely a road class rank (5 freeway/main, 2 main/country, 1 country/district, 0 local/unpaved); 6 and 15 are freeway road properties (6 = 0 seen on ramps); 7, 17 and others are not identified yet.";
CM_ SG_ 1124 PSD_Ges_Geschwindigkeit "Read the code as the lower bound of its band: 40 km/h school zones are 9 and 110 km/h freeway is 17 on a 2016 Golf Mk7 (AU). The nav map can differ from posted signs.";
CM_ BO_ 1124 "Predictive route data (PSD), multiplexed: 0 system info, 1 more segment attributes, 2 speed limits, 3 vehicle position (lat/long, heading), 4 gradients.";
CM_ SG_ 302 ACC_Hold_Request "Active request for ABS brake hold in ACC_Hold_Type";
CM_ SG_ 302 ACC_Boost_Request "Hybrid engine start related";
CM_ SG_ 302 ACC_Freewheel_Request "Active request for DSG sailing/coasting in ACC_Freewheel_Type";
CM_ SG_ 302 ACC_Hold_Release "Request to ABS to release brake hold";
CM_ SG_ 302 ACC_Accel_Secondary "Target acceleration of the secondary controller";
CM_ SG_ 302 ACC_Accel_TSK "Mirror of request to TSK to implement a target acceleration";
CM_ SG_ 870 Hazard_Switch "Four-way flashers active";
CM_ SG_ 870 Comfort_Signal_Left "Comfort turn signal active, left";
CM_ SG_ 870 Comfort_Signal_Right "Comfort turn signal active, right";
CM_ SG_ 870 Left_Turn_Exterior_Bulb_1 "Probably front";
CM_ SG_ 870 Right_Turn_Exterior_Bulb_1 "Probably front";
CM_ SG_ 870 Left_Turn_Exterior_Bulb_2 "Probably rear";
CM_ SG_ 870 Right_Turn_Exterior_Bulb_2 "Probably rear";
CM_ SG_ 870 Fast_Send_Rate_Active "CAN message send rate";
CM_ SG_ 919 LDW_DLC "Probable DLC (distance to line crossing)";
CM_ SG_ 919 LDW_TLC "Probable TLC (time to line crossing)";
CM_ SG_ 919 LDW_Unknown "Might be a steering pressed / driver active flag";
CM_ SG_ 919 Alert_Message "Static table of alert messages to be invoked in the instrument cluster, some with or without beeps, 0 = no current message";
CM_ SG_ 919 LDW_Direction "Left/right indicator for DLC and TLC";
CM_ SG_ 919 Right_Lane_Status "Display brightness range, 0 = no lane, 3 = full brightness";
CM_ SG_ 919 Left_Lane_Status "Display brightness range, 0 = no lane, 3 = full brightness";
CM_ SG_ 919 Kombi_Lamp_Orange "Enables orange LDW light in instrument cluster";
CM_ SG_ 919 Kombi_Lamp_Green "Enables green LDW light in instrument cluster";
CM_ SG_ 780 Folgefahrt "Following another vehicle";
CM_ SG_ 780 SetAbstand "Set following distance";
CM_ SG_ 780 Abstand "Following distance";
CM_ SG_ 780 SetSpeed "ACC set speed";
CM_ SG_ 780 ACC_Abstandsindex "Lead vehicle icon position on the cluster ACC gap graphic, relative to the set time gap, not a distance. 0 = no radar target. 34 = floor, lead inside the set gap (time gap below ~1.0 s at distance setting 1). ~100 = lead at the set gap. Above the floor approx 607*ln(dRel/(3.0+0.85*vEgo))+92 (fit on a 2016 Golf Mk7 against vision dRel, rmse ~80, display lags ~0.6 s).";
CM_ SG_ 391 MO_Waehlpos "Traditional PRND plus B-mode aggressive regen, B-mode mapped to Drive";
CM_ SG_ 1720 KBI_BCmE_aktiv "Anzeige BCmE aktiv (BCmE-Screen oder Einsparhinweis in der Anzeige)";
CM_ SG_ 1720 KBI_Max_Tankinhalt "Mitteilung des maximalen Tankinhalts an das Reichweitenmodul";
CM_ SG_ 1720 KBI_Nachtanken_erkannt "Statusinformation Nachtankmodus";
CM_ SG_ 1720 KBI_Reifenumfang "Mittlerer Radumfang aus der K-Zahl gerechnet in Millimeter.  Byte 2 Bit 5,4 reserviert, Byte 2 Bit 3..0 und Byte 1 Bit 7..0; Wertebereich 0..4096 mm
";
CM_ SG_ 1720 KBI_Reifenumfang_Sekundaer "Fahrzeuge mit unterschiedlichen Reifenumfängen Vorderachse / Hinterachse:

Primärachse: KBI_Reifenumfang
Sekundärachse: KBI_Reifenumfang_Sekundaer
";
CM_ SG_ 1720 KBI_Sparhinweis_quittiert "angezeigter Sparhinweis ist quittiert. Signal wird nach zwei Sendebotschaften wieder auf '0' gesetzt.";
CM_ SG_ 1720 KBI_Tankfuellstand_Prozent "Tankfüllstand in %";
CM_ SG_ 1720 KBI_Tankinhalt_hochaufl "angezeigter Tankinhalt hochauflösend zur Restreichweitenberechnung";
CM_ SG_ 1720 KBI_Variante "Zeigt an ob es sich um ein konventionelles Zeiger-Kombiinstrument handelt oder um eine Volldisplay-Kombiinstrument";
CM_ SG_ 1720 KBI_Variante_USA "In diesem Signal wird die HW-Variante des Kombis ausgegeben, ACC plausibilisiert auf dieses Signal hin seine US-Codierung";

VAL_ 1440 LS_Helligkeit_IR 254 "Init" 255 "error" ;
VAL_ 1440 LS_Helligkeit_FW 1022 "Init" 1023 "error" ;
VAL_ 1440 LS_defekt 0 "OK" 1 "faulty" ;
VAL_ 1440 LS_Verbau 0 "Init" 1 "Lichtsensor_fitted" ;
VAL_ 1440 RS_Regenmenge 0 "0" 1 "0,0 to 0,3" 2 "0,31 to 1,4" 3 "1,41 to 2,0" 4 "2,01 to 2,8" 5 "2,81 to 3,3" 6 "3,31 to 4,0" 7 "4,01 to 5,0" 8 "5,01 to 7,0" 9 "7,01 to 9,0" 10 "9,01 to 11,0" 11 "11,01 to 15,0" 12 "15,01 to 22,0" 13 ">22,01" 14 "Init" 15 "error" ;
VAL_ 1440 RS_Schwall 0 "Off" 1 "On" ;
VAL_ 1440 RS_Verbau 0 "Init" 1 "Regensensor fitted" ;
VAL_ 1440 RS_Verglasung_schliessen 0 "Verglasung not close" 1 "Verglasung close" ;
VAL_ 1440 RS_defekt 0 "OK" 1 "faulty" ;
VAL_ 1440 RS_Wischergeschwindigkeit 0 "no wiping" 1 "42 Huebe/min" 2 "45 Huebe/min" 3 "48 Huebe/min" 4 "51 Huebe/min" 5 "54 Huebe/min" 6 "57 Huebe/min" 7 "60 Huebe/min" ;
VAL_ 1440 RLS_Vorfeldhelligkeit_Boost 0 "greater_24413_Lux" 1 "to_24413_Lux" 2 "to_22193_Lux" 3 "to_20176_Lux" 4 "to_18342_Lux" 5 "to_16647_Lux" 6 "to_15158_Lux" 7 "to_13780_Lux" 8 "to_12527_Lux" 9 "to_11388_Lux" 10 "to_10353_Lux" 11 "to_9412_Lux" 12 "to_8556_Lux" 13 "to_7778_Lux" 14 "to_7071_Lux" 15 "to_6428_Lux" ;
VAL_ 1624 LV_Standlicht_Anzeige 0 "not active" 1 "active" ;
VAL_ 1624 LV_Abblendlicht_Anzeige 0 "inactive" 1 "active" ;
VAL_ 1624 LV_Fernlicht_Anzeige 0 "not active" 1 "active" ;
VAL_ 1624 LV_Nebellicht_Anzeige 0 "not active" 1 "active" ;
VAL_ 1624 LV_Nebelschlusslicht_Anzeige 0 "not active" 1 "active" ;
VAL_ 1624 LV_Tagfahrlicht_Anzeige 0 "not active" 1 "active" ;
VAL_ 1624 LV_AFL_aktiv_Anzeige 0 "not active" 1 "active" ;
VAL_ 1624 LV_AFL_defekt 0 "OK" 1 "faulty" ;
VAL_ 1624 LV_Blinker_li_def 0 "OK" 1 "faulty" ;
VAL_ 1624 LV_Standlicht_li_def 0 "OK" 1 "faulty" ;
VAL_ 1624 LV_Abblendlicht_li_def 0 "OK" 1 "faulty" ;
VAL_ 1624 LV_Fernlicht_li_def 0 "OK" 1 "faulty" ;
VAL_ 1624 LV_Nebellicht_li_def 0 "OK" 1 "faulty" ;
VAL_ 1624 LV_Blk_li_Seite_def 0 "OK" 1 "faulty" ;
VAL_ 1624 LV_Tagfahrlicht_li_def 0 "OK" 1 "faulty" ;
VAL_ 1624 LV_FLA_aktiv_Anzeige 0 "off" 1 "on" ;
VAL_ 1624 LV_FLA_defekt 0 "i.O." 1 "FLA faulty" ;
VAL_ 1624 LV_FLA_Sensor_blockiert 0 "i.O." 1 "FLA-Sensor blocked" ;
VAL_ 1624 LV_Blinker_re_def 0 "OK" 1 "faulty" ;
VAL_ 1624 LV_Standlicht_re_def 0 "OK" 1 "faulty" ;
VAL_ 1624 LV_Abblendlicht_re_def 0 "OK" 1 "faulty" ;
VAL_ 1624 LV_Fernlicht_re_def 0 "OK" 1 "faulty" ;
VAL_ 1624 LV_Nebellicht_re_def 0 "OK" 1 "faulty" ;
VAL_ 1624 LV_Blk_re_Seite_def 0 "OK" 1 "faulty" ;
VAL_ 1624 LV_Tagfahrlicht_re_def 0 "OK" 1 "faulty" ;
VAL_ 1624 LV_Aussenlicht_def 0 "OK" 1 "faulty" ;
VAL_ 1624 LV_Abblendlicht_TFL_li_def 0 "OK" 1 "faulty" ;
VAL_ 1624 LV_Nebellicht_TFL_li_def 0 "OK" 1 "faulty" ;
VAL_ 1624 LV_Standlicht_TFL_li_def 0 "OK" 1 "faulty" ;
VAL_ 1624 LV_Abblend_Fernlicht_li_def 0 "OK" 1 "faulty" ;
VAL_ 1624 LV_Abblendlicht_TFL_re_def 0 "OK" 1 "faulty" ;
VAL_ 1624 LV_Nebellicht_TFL_re_def 0 "OK" 1 "faulty" ;
VAL_ 1624 LV_Standlicht_TFL_re_def 0 "OK" 1 "faulty" ;
VAL_ 1624 LV_Abblend_Fernlicht_re_def 0 "OK" 1 "faulty" ;
VAL_ 1624 LV_Abbiegelicht_li_def 0 "OK" 1 "faulty" ;
VAL_ 1624 LV_Abbiegelicht_re_def 0 "OK" 1 "faulty" ;
VAL_ 1624 BCM1_Linksverkehr 0 "right_hand_traffic" 1 "left_hand_traffic" ;
VAL_ 1624 BCM1_Licht_Dunkelheit_aktiv 0 "inactive" 1 "active" ;
VAL_ 1624 LV_LED_Scheinwerfer_li_def 0 "OK" 1 "faulty" ;
VAL_ 1624 LV_LED_Scheinwerfer_re_def 0 "OK" 1 "faulty" ;
VAL_ 1624 LV_Blinker_VL_aktiv 0 "inactive" 1 "active" ;
VAL_ 1624 LV_Blinker_VR_aktiv 0 "inactive" 1 "active" ;
VAL_ 1624 LV_MXB_Status_Anzeige 0 "MXB_off" 1 "MXB_controlling" 2 "MXB_volles_high_beam" 3 "MXB_and_Laser_active" ;
VAL_ 1646 KL_Geblaese_Status 0 "Geblaese_off" 1 "Geblaesestufe_10" 2 "Geblaesestufe_20" 3 "Geblaesestufe_30" 4 "Geblaesestufe_40" 5 "Geblaesestufe_50" 6 "Geblaesestufe_60" 7 "Geblaesestufe_70" 8 "Geblaesestufe_80" 9 "Geblaesestufe_90" 10 "Geblaesestufe_100" 14 "Init" 15 "error" ;
VAL_ 1646 KL_Innen_Temp 253 "not_fitted" 254 "not_available" 255 "error" ;
VAL_ 1175 PH_Visualisierung 0 "Off" 1 "Angefragt" 2 "InAnzeige" 3 "Abgefordert" 6 "Init" 7 "error" ;
VAL_ 1175 PDC_Tonausgabe_Front 0 "no_Ton" 1 "Intervallton_1" 2 "Intervallton_2" 3 "Intervallton_3" 4 "Intervallton_4" 5 "Intervallton_5" 6 "Dauerton" 7 "Fehlerton" 8 "RCTATon" ;
VAL_ 1175 PDC_Tonausgabe_Heck 0 "no_Ton" 1 "Intervallton_1" 2 "Intervallton_2" 3 "Intervallton_3" 4 "Intervallton_4" 5 "Intervallton_5" 6 "Dauerton" 7 "Fehlerton" 8 "Erstwarnton_rear" 9 "RCTATon" ;
VAL_ 1175 PH_nachtr_Stopp_Anf 0 "not_requested" 1 "requested" ;
VAL_ 1175 PH_Abschaltursache 0 "no, or. System active" 1 "shutdown by Herausnahme R-gear" 2 "shutdown over speed" 3 "shutdown over PDC-button" 4 "shutdown due_to PLA" 5 "shutdown by KL 15 Bit = 0" 6 "tbd." 7 "error-/gestört state, System noch active" ;
VAL_ 1175 PH_Opt_Anzeige_V_ein 0 "optische display front not active" 1 "optische display front activated" ;
VAL_ 1175 PH_Opt_Anzeige_H_ein 0 "Optische display off" 1 "optische display rear activated" ;
VAL_ 1175 PH_Opt_Anz_V_Hindernis 0 "optische display front meldet no obstacle" 1 "optische display front meldet obstacle in Warnbereich" ;
VAL_ 1175 PH_Opt_Anz_H_Hindernis 0 "optische display rear meldet no obstacle" 1 "optische display rear meldet obstacle in Warnbereich" ;
VAL_ 1175 PH_Tongeber_V_aktiv 0 "Tongeber front not active" 1 "Tongeber front  active" ;
VAL_ 1175 PH_Tongeber_H_aktiv 0 "Tongeber rear not active" 1 "Tongeber rear active" ;
VAL_ 1175 PH_Tongeber_mute 0 "Tongeber not stummgeschaltet" 1 "Tongeber stummgeschaltet" ;
VAL_ 1175 PH_Anf_Audioabsenkung 0 "No_Audioabsenkung" 1 "request_Audioabsenkung" ;
VAL_ 1175 PH_Tongeber_H_verfuegbar 0 "not available" 1 "available" ;
VAL_ 1175 PLA_Anf_Aufschaltung_RVC 0 "No_RVC_Aufschalteanf" 1 "RVC_Aufschalteanforderung" ;
VAL_ 1175 PH_Taster 0 "button_not_pressed" 1 "button_pressed" 2 "reserved" 3 "error" ;
VAL_ 1175 PH_Anf_Verdeck 0 "soft_top_operation_enabled" 1 "soft_top_operation_lock" 2 "reserved" 3 "reserved" ;
VAL_ 1175 PH_StartStopp_Info 0 "engine_running_not_required_(stop_enabled)" 1 "engine_cranking_not_mandatory_required_(stop_prohibited,no_start_request)" 2 "engine_cranking_mandatory_required_(start_request)" 3 "system_error" ;
VAL_ 1175 PH_Stoermeldung 0 "no_display_no_Gong" 1 "text_message_PDC_rear_faulty_with_Gong" 2 "text_message_PDC_rear_faulty_without_Gong" 3 "text_message_PDC_front_faulty_with_Gong" 4 "text_message_PDC_front_faulty_without_Gong" 5 "text_message_PDC_faulty_with_Gong" 6 "text_message_PDC_faulty_without_Gong" 7 "text_message_PDC_seitlich_faulty_with_Gong" 8 "text_message_PDC_seitlich_faulty_without_Gong" ;
VAL_ 1175 PH_defekt 0 "PH active" 1 "PH wurde aufgrund eines Defektes deactivated" ;
VAL_ 1175 PH_gestoert 0 "PH active" 1 "PH wurde on reason one fault tempraer deactivated" ;
VAL_ 1175 PH_Systemzustand 0 "Anlage off" 1 "Anlage by engage R-gear activated" 2 "Anlage manual by button activated" 3 "Anlage automatisch activated" 4 "Anlage by ARA activated" 6 "Init - Initialisierungsphase after Kl. 15 on / Reset" 7 "error-/gestört state, System noch active" ;
VAL_ 1175 PH_Display_Kundenwunsch 0 "display off" 1 "graphic" 2 "Rear View" 3 "automatisch" ;
VAL_ 2589283745 RDR_QBit_Objekte 0 "valid_value" 1 "substitute_Init_or_error_value" ;
VAL_ 2589283745 RDR_RNS2_PositionX 63 "Init" ;
VAL_ 2589283745 RDR_RNS1_PositionX 63 "Init" ;
VAL_ 2589283745 RDR_LNS2_PositionX 63 "Init" ;
VAL_ 2589283745 RDR_WZO_GeschwAbsX 127 "Init" ;
VAL_ 2589283745 RDR_WZO_PositionX 63 "Init" ;
VAL_ 2589283745 RDR_VZO_PositionX 63 "Init" ;
VAL_ 2589283745 RDR_RNS1_GeschwAbsX 127 "Init" ;
VAL_ 2589283745 RDR_LNS1_PositionX 63 "Init" ;
VAL_ 2589283745 RDR_LNS1_GeschwAbsX 127 "Init" ;
VAL_ 896 US_Sende_Modus 0 "no_for_the_ACC_SG_relevant_distance_values_be_sent" 1 "4K_ext_range__10_signal_paths_available__4m" 2 "4K_norm_range__10_signal_paths_available__2m" 3 "6K_ext_range__16_signal_paths_available__4m" 4 "6K_norm_range__16_signal_paths_available__2m" 5 "2K_ext_range__2_signal_paths_available__4m" 6 "mode_switch__ext_>_norm__or__norm_>_ext" 7 "blindness_check" 8 "4K_ext_range__12_signal_paths_available_4m" 9 "4K_norm_range__12_signal_paths_available_2m" 10 "6K_ext_range__18_signal_paths_available_4m" 11 "6K_norm_range__18_signal_paths_available_2m" 15 "error" ;
VAL_ 896 US_relevanter_Fehler 0 "no_relevant_error" 1 "relevant_error" ;
VAL_ 896 US_relevante_Nichtverfuegbarkeit 0 "available" 1 "not_available" ;
VAL_ 896 US_Freisicht_nio 0 "clear_view_OK" 1 "clear_view_not_OK" ;
VAL_ 896 US_blindness_detected 0 "blindness_not_detected" 1 "blindness_detected" ;
VAL_ 896 US_Sende_Modus_hinten 0 "no_for_the_ACC_SG_relevant_distance_values_be_sent" 5 "2K_ext_range__2_signal_paths_available__4m" 6 "mode_switch__ext_>_norm__or__norm_>_ext" 7 "blindness_check" 15 "error" ;
VAL_ 896 US_Freie_Weglaenge_Heck_Typ 0 "maximum_measuring_range" 1 "obstacle_detected" ;
VAL_ 896 US_Freie_Weglaenge_Heck 510 "Init" 511 "error" ;
VAL_ 896 APS_Master_Sendestatus 0 "slow_cycle_time_active" 1 "fast_cycle_time_active" ;
VAL_ 896 US_Freie_Weglaenge_Front_Typ 0 "maximum_measuring_range" 1 "obstacle_detected" ;
VAL_ 896 US_Freie_Weglaenge_Front 509 "free_path_length_greater_5m" 510 "Init" 511 "error" ;
VAL_ 1654 StSt_Koord_Wiederstart_Anz_09 0 "no_display" 1 "traffic_light_Info" ;
VAL_ 1654 StSt_Koord_Wiederstart_Anz_10 0 "no_display" 1 "Race_Mode" ;
VAL_ 1654 StSt_Koord_Wiederstart_Anz_11 0 "no_display" 1 "restart_PEA" ;
VAL_ 1654 MO_Wiederstart_Anz_01 0 "no_display" 1 "engine_temperature" ;
VAL_ 1654 MO_Wiederstart_Anz_02 0 "no_display" 1 "BKV_vacuum" ;
VAL_ 1654 MO_Wiederstart_Anz_03 0 "no_display" 1 "SCR_System" ;
VAL_ 1654 MO_Wiederstart_Anz_Std 0 "no_display" 1 "Standard_restart_reason" ;
VAL_ 1654 MO_Stoppverbot_Anz_01 0 "no_display" 1 "exhaust_system" ;
VAL_ 1654 MO_Stoppverbot_Anz_02 0 "no_display" 1 "engine_temperature_Min" ;
VAL_ 1654 MO_Stoppverbot_Anz_03 0 "no_display" 1 "engine_temperature_Max" ;
VAL_ 1654 MO_Stoppverbot_Anz_04 0 "no_display" 1 "ambient_air_density" ;
VAL_ 1654 MO_Stoppverbot_Anz_05 0 "no_display" 1 "brake_vacuum" ;
VAL_ 1654 MO_Stoppverbot_Anz_06 0 "no_display" 1 "adaptations" ;
VAL_ 1654 MO_Stoppverbot_Anz_07 0 "no_display" 1 "gear_sensor" ;
VAL_ 1654 MO_Stoppverbot_Anz_08 0 "no_display" 1 "diagnosis_tank_venting" ;
VAL_ 1654 MO_Stoppverbot_Anz_09 0 "no_display" 1 "FlexFuel_SCR_CNG" ;
VAL_ 1654 MO_Stoppverbot_Anz_10 0 "no_display" 1 "OPF_DPF_Regeneration" ;
VAL_ 1654 MO_Stoppverbot_Anz_11 0 "no_display" 1 "sporadic_stop_prevention" ;
VAL_ 1654 MO_Stoppverbot_Anz_Std 0 "no_display" 1 "Standard_stop_veto_reason" ;
VAL_ 1654 StSt_Koord_Stoppverbot_Anz_20 0 "traffic_light_prevents_engine_stop_not" 1 "traffic_light_prevents_engine_stop" ;
VAL_ 1654 StSt_Koord_Stoppverbot_Anz_21 0 "Race_Mode_prevents_engine_stop_not" 1 "Race_Mode_prevents_engine_stop" ;
VAL_ 1654 StSt_Koord_Wiederstart_Anz_Std 0 "no_display" 1 "Standard_restart_reason" ;
VAL_ 1654 StSt_Koord_Status_Bremspedalkzpt 0 "brake_pedal_start_possible" 1 "no_brake_pedal_start_possible" ;
VAL_ 1654 StSt_Koord_Wiederstart_Anz_01 0 "no_display" 1 "clutch_brake" ;
VAL_ 1654 StSt_Koord_Wiederstart_Anz_02 0 "no_display" 1 "accelerator_pedal" ;
VAL_ 1654 StSt_Koord_Wiederstart_Anz_03 0 "no_display" 1 "button" ;
VAL_ 1654 StSt_Koord_Wiederstart_Anz_04 0 "no_display" 1 "shifting_after_R" ;
VAL_ 1654 StSt_Koord_Wiederstart_Anz_05 0 "no_display" 1 "rolling_start" ;
VAL_ 1654 StSt_Koord_Wiederstart_Anz_06 0 "no_display" 1 "emergency_start" ;
VAL_ 1654 StSt_Koord_Wiederstart_Anz_07 0 "no_display" 1 "steering_wheel" ;
VAL_ 1654 StSt_Koord_Wiederstart_Anz_08 0 "no_display" 1 "Offroad_Sport_and_ESP_button" ;
VAL_ 1654 StSt_Koord_Stoppverbot_Anz_01 0 "no_display" 1 "vehicle_tilt" ;
VAL_ 1654 StSt_Koord_Stoppverbot_Anz_02 0 "no_display" 1 "repeat_stop_lock" ;
VAL_ 1654 StSt_Koord_Stoppverbot_Anz_03 0 "no_display" 1 "manoeuvre_detection_MQ_DQ" ;
VAL_ 1654 StSt_Koord_Stoppverbot_Anz_04 0 "no_display" 1 "tamper_protection" ;
VAL_ 1654 StSt_Koord_Stoppverbot_Anz_05 0 "no_display" 1 "button_start_stop_switched_off" ;
VAL_ 1654 StSt_Koord_Stoppverbot_Anz_06 0 "no_display" 1 "bonnet" ;
VAL_ 1654 StSt_Koord_Stoppverbot_Anz_07 0 "no_display" 1 "driver_seatbelt" ;
VAL_ 1654 StSt_Koord_Stoppverbot_Anz_08 0 "no_display" 1 "driver_door" ;
VAL_ 1654 StSt_Koord_Stoppverbot_Anz_09 0 "no_display" 1 "accelerator_pedal" ;
VAL_ 1654 StSt_Koord_Stoppverbot_Anz_10 0 "no_display" 1 "steering_angle_steering_angle_rate" ;
VAL_ 1654 StSt_Koord_Stoppverbot_Anz_11 0 "no_display" 1 "trailer" ;
VAL_ 1654 StSt_Koord_Stoppverbot_Anz_12 0 "no_display" 1 "immobiliser_active" ;
VAL_ 1654 StSt_Koord_Stoppverbot_Anz_13 0 "no_display" 1 "permanent_driver_absent" ;
VAL_ 1654 StSt_Koord_Stoppverbot_Anz_14 0 "no_display" 1 "temporary_driver_absent" ;
VAL_ 1654 StSt_Koord_Stoppverbot_Anz_15 0 "no_display" 1 "Offroad_Sport_and_ESP_button" ;
VAL_ 1654 StSt_Koord_Stoppverbot_Anz_16 0 "no_display" 1 "neutral_gear" ;
VAL_ 1654 StSt_Koord_Stoppverbot_Anz_17 0 "driver_action_prevents_engine_stop_not" 1 "missing_driver_action_prevents_engine_stop" ;
VAL_ 1654 StSt_Koord_Stoppverbot_Anz_Std 0 "no_display" 1 "Standard_stop_veto_reason" ;
VAL_ 1654 StSt_Koord_Stoppverbot_Anz_18 0 "PSD_prevents_engine_stop_not" 1 "PSD_prevents_engine_stop" ;
VAL_ 1654 StSt_Koord_Stoppverbot_Anz_19 0 "short_stop_prevents_engine_stop_not" 1 "short_stop_prevents_engine_stop" ;
VAL_ 1654 MO_StaGluehk 15 "error" ;
VAL_ 385 VZE_Anzeigemodus 0 "EU_RDW" 1 "USA" 2 "Canada" 3 "China" ;
VAL_ 385 VZE_Hinweistext 0 "no_notice_text" ;
VAL_ 385 VZE_Akustik_Limitwechsel 0 "no_acoustic_signal" 1 "acoustic_signal_on" ;
VAL_ 385 VZE_Modus_OptischeWarnung 0 "constant" 1 "flashing" ;
VAL_ 385 VZE_Anzeigeunterdrueck_Zeichen_3 0 "display_relevant" 1 "not_display_relevant" ;
VAL_ 385 VZE_Anzeigeunterdrueck_Zeichen_2 0 "display_relevant" 1 "not_display_relevant" ;
VAL_ 385 VZE_Verkehrszeichen_1 0 "no_traffic_sign" ;
VAL_ 385 VZE_Verkehrszeichen_2 0 "no_traffic_sign" ;
VAL_ 385 VZE_Verkehrszeichen_3 0 "no_traffic_sign" ;
VAL_ 385 VZE_Warnung_Verkehrszeichen_1 0 "no_warning_initial_value_error_value" 1 "warning" ;
VAL_ 385 VZE_Warnung_Verkehrszeichen_2 0 "no_warning_initial_value_error_value" 1 "warning" ;
VAL_ 385 VZE_Warnung_Verkehrszeichen_3 0 "no_warning_initial_value_error_value" 1 "warning" ;
VAL_ 385 VZE_Zusatzschild_1 0 "no_supplementary_sign_initial_value_error_value" ;
VAL_ 385 VZE_Zusatzschild_2 0 "no_supplementary_sign_initial_value_error_value" ;
VAL_ 385 VZE_Zusatzschild_3 0 "no_supplementary_sign_initial_value_error_value" ;
VAL_ 385 VZE_Anzeigeunterdrueck_Zeichen_1 0 "display_relevant" 1 "not_display_relevant" ;
VAL_ 385 VZE_Zeichen_01_KameraWied 0 "inactive" 1 "active" ;
VAL_ 385 VZE_Zeichen_02_KameraWied 0 "inactive" 1 "active" ;
VAL_ 385 VZE_Zeichen_03_KameraWied 0 "inactive" 1 "active" ;
VAL_ 385 VZE_Zeichen_01_Kamera 0 "not_detected" 1 "detected" ;
VAL_ 385 VZE_Zeichen_01_Karte 0 "inactive" 1 "active" ;
VAL_ 385 VZE_Zeichen_01_Gesetz 0 "not_detected" 1 "detected" ;
VAL_ 385 VZE_Zeichen_02_Kamera 0 "not_detected" 1 "detected" ;
VAL_ 385 VZE_Zeichen_02_Karte 0 "inactive" 1 "active" ;
VAL_ 385 VZE_Zeichen_02_Gesetz 0 "not_detected" 1 "detected" ;
VAL_ 385 VZE_Zeichen_03_Kamera 0 "not_detected" 1 "detected" ;
VAL_ 385 VZE_Zeichen_03_Karte 0 "inactive" 1 "active" ;
VAL_ 385 VZE_Zeichen_03_Gesetz 0 "not_detected" 1 "detected" ;
VAL_ 385 VZE_Gong 0 "Gong_inactive" 1 "Gong_active" ;
VAL_ 668 VZE_Akustik_Limitwechsel_Status 0 "no_acoustic_signal" 1 "acoustic_signal_on" ;
VAL_ 668 VZE_SLWF_Status 0 "Init" 1 "active" 2 "inactive" ;
VAL_ 668 VZE_Anzeigeunterdrueck_Zeichen_5 0 "display_relevant" 1 "not_display_relevant" ;
VAL_ 668 VZE_Zeichen_05_KameraWied 0 "inactive" 1 "active" ;
VAL_ 668 VZE_Zeichen_05_Kamera 0 "not_detected" 1 "detected" ;
VAL_ 668 VZE_Verkehrszeichen_4 0 "no_traffic_sign" ;
VAL_ 668 VZE_Verkehrszeichen_5 0 "no_traffic_sign" ;
VAL_ 668 VZE_Anhaenger_Vmax 14 "Init" 15 "error" ;
VAL_ 668 VZE_Zeichen_04_Gesetz 0 "not_detected" 1 "detected" ;
VAL_ 668 VZE_Zeichen_04_Kamera 0 "not_detected" 1 "detected" ;
VAL_ 668 VZE_Zeichen_04_KameraWied 0 "inactive" 1 "active" ;
VAL_ 668 VZE_Zeichen_04_Karte 0 "inactive" 1 "active" ;
VAL_ 668 VZE_Warnung_Verkehrszeichen_4 0 "no_warning_initial_value_error_value" 1 "warning" ;
VAL_ 668 VZE_Warnung_Verkehrszeichen_5 0 "no_warning_initial_value_error_value" 1 "warning" ;
VAL_ 668 VZE_Zeichen_05_Gesetz 0 "not_detected" 1 "detected" ;
VAL_ 668 VZE_Zusatzschild_4 0 "no_supplementary_sign_initial_value_error_value" ;
VAL_ 668 VZE_Zusatzschild_5 0 "no_supplementary_sign_initial_value_error_value" ;
VAL_ 668 VZE_Baustelle 0 "No_roadworks" 1 "roadworks_detected" ;
VAL_ 668 VZE_Zeichen_05_Karte 0 "inactive" 1 "active" ;
VAL_ 668 VZE_Zeichen_05_Entfernung 0 "Init" ;
VAL_ 668 VZE_Zeichen_05_Entfernung_StdA 0 "Init" ;
VAL_ 668 VZE_Anzeigeunterdrueck_Zeichen_4 0 "display_relevant" 1 "not_display_relevant" ;
VAL_ 806 BV_Linie_01_Farbe 0 "no_line" 1 "white" 2 "red" 3 "yellow" 4 "other" 5 "not_defined" 6 "not_defined" 7 "not_defined" ;
VAL_ 806 BV_Linie_01_Liniennummer 0 "no_line" ;
VAL_ 806 BV_Linie_01_Typ 0 "no_line" 1 "solid" 2 "dashed" 3 "kerb" 4 "grass" 5 "Botts_dots" 6 "other" 7 "not_defined" ;
VAL_ 807 BV_Linie_02_Farbe 0 "no_line" 1 "white" 2 "red" 3 "yellow" 4 "other" 5 "not_defined" 6 "not_defined" 7 "not_defined" ;
VAL_ 807 BV_Linie_02_Liniennummer 0 "no_line" ;
VAL_ 807 BV_Linie_02_Typ 0 "no_line" 1 "solid" 2 "dashed" 3 "kerb" 4 "grass" 5 "Botts_dots" 6 "other" 7 "not_defined" ;
VAL_ 808 BV_Linie_03_Farbe 0 "no_line" 1 "white" 2 "red" 3 "yellow" 4 "other" 5 "not_defined" 6 "not_defined" 7 "not_defined" ;
VAL_ 808 BV_Linie_03_Liniennummer 0 "no_line" ;
VAL_ 808 BV_Linie_03_Typ 0 "no_line" 1 "solid" 2 "dashed" 3 "kerb" 4 "grass" 5 "Botts_dots" 6 "other" 7 "not_defined" ;
VAL_ 809 BV_Linie_04_Farbe 0 "no_line" 1 "white" 2 "red" 3 "yellow" 4 "other" 5 "not_defined" 6 "not_defined" 7 "not_defined" ;
VAL_ 809 BV_Linie_04_Liniennummer 0 "no_line" ;
VAL_ 809 BV_Linie_04_Typ 0 "no_line" 1 "solid" 2 "dashed" 3 "kerb" 4 "grass" 5 "Botts_dots" 6 "other" 7 "not_defined" ;
VAL_ 780 ACC_Wunschgeschw_02 1023 "keine_Anzeige" ;
VAL_ 780 ACC_Status_Prim_Anz 0 "Symbol nicht beleuchtet" 1 "Farbe 1 (typisch 'gruen')" 2 "Farbe 2 (typisch 'rot')" 3 "Farbe 3 (typisch 'gelb')" ;
VAL_ 780 ACC_Abstandsindex 0 "Sonderanzeige_graue_Fahrbahn" 1022 "Sonderanzeige_graue_Fahrbahn" 1023 "Sonderanzeige_Fahrbahn_mit_gruenem_roten_Bereich" ;
VAL_ 780 ACC_Akustik_02 0 "keine_Akustik" 1 "hochpriore_Akustik" 2 "niederpriore_Akustik" 3 "hochpriore_Dauerakustik" ;
VAL_ 780 ACC_Warnung_Verkehrszeichen_1 0 "keine_Warnung_Initialwert" 1 "Warnung" ;
VAL_ 780 ACC_Gesetzte_Zeitluecke 0 "keine_Anzeige" 1 "Zeitluecke_1" 2 "Zeitluecke_2" 3 "Zeitluecke_3" 4 "Zeitluecke_4" 5 "Zeitluecke_5" 6 "nicht_definiert" 7 "nicht_definiert" ;
VAL_ 780 ACC_Optischer_Fahrerhinweis 0 "optischer_Fahrerhinweis_AUS" 1 "optischer_Fahrerhinweis_EIN" ;
VAL_ 780 ACC_Typ_Tachokranz 0 "Tachokranz_lang" 1 "Tachokranz_kurz" ;
VAL_ 780 ACC_Anzeige_Zeitluecke 0 "Anzeige_Zeitluecke_nicht_angefordert" 1 "Anzeige_Zeitluecke_angefordert" ;
VAL_ 780 ACC_Tachokranz 0 "Tachokranz_nicht_beleuchtet" 1 "Tachokranz_beleuchtet" ;
VAL_ 780 ACC_Display_Prio 0 "hoechste_Prio" 1 "mittlere_Prio" 2 "geringe_Prio" 3 "keine_Prio" ;
VAL_ 780 ACC_Relevantes_Objekt 0 "Symbol_nicht_beleuchtet" 1 "Farbe_1_typisch_gruen" 2 "Farbe_2_typisch_rot" 3 "Farbe_3_typisch_gelb" ;
VAL_ 780 ACC_Texte_Primaeranz 0 "keine Anzeige" 1 "ACC nicht verfuegbar !" 2 "Auto_Auto_ _ _" 3 "Auto_ _Auto_ _" 4 "Auto_ _ _Auto_" 5 "Auto_ _ _ _Auto" 6 "Auto_Auto_ _ _ Gong (durchgestrichen)" 7 "Auto_ _Auto_ _ Gong (durchgestrichen)" 8 "Auto_ _ _Auto_ Gong (durchgestrichen)" 9 "Auto_ _ _ _Auto Gong (durchgestrichen)" 10 "ACC bereit" 11 "keine Abstandsregelung" 12 "ACC Sensor Sicht !" 13 "ACC nicht verfuegbar" 14 "o  o  o" 15 "Hochschalten" 16 "ESP Eingriff" 17 "Herunterschalten" 18 "Parkbremse !" 19 "Geschwindigkeitsgrenze" 20 "Waehlhebelposition !" 21 "VDA ACC-Symbol YYY km/h / mph" 22 "Tempolimit XXX km/h / mph" 23 "Kurve XXX km/h / mph" 24 "ACC Abschaltung" 25 "Symbol 'Eieruhr'" 26 "!" 27 "--- km/h / mph" 28 "XXX km/h / mph (Schriftart 2)" 29 "Lenkradwinkel" 30 "Anfahren bestaetigen" 31 "Fahrzeug verloren" 32 "Im Stand nicht moeglich" 33 "Ungueltiger Anfahrbefehl" 34 "Tuer offen !" 35 "Fahrer Gurtschloss offen !" 36 "Schalthebelposition !" 37 "Drehzahl !" 38 "Kurvenassistent aus" 39 "Tempolimit aus" 40 "Abbiegeassistent" 41 "Ortsanfang XXX km/h / mph" 42 "Ortsende XXX km/h / mph" 43 "Tempolimit Ende XXX km/h / mph" 44 "HDC aktiv" 45 "braking guard Bremsruck" 46 "braking guard aus" 47 "braking guard aus" 48 "Uebernehmen !" 49 "Steigung zu gross" 50 "Stehendes Objekt voraus" 51 "SET / 'GRA Symbol'___xxx km/h / mph" 52 "SET / 'GRA Symbol' xxx km/h / mph" 53 "ACC aus" 54 "ACC startet" 55 "ACC reinigen" 56 "ACC Fehler" 57 "ACC haelt an !" 58 "Bremse betaetigen !" 59 "Kupplung betaetigt" 60 "LIM AUS" 61 "LIM AKTIV" 62 "LIM PASSIV" 63 "LIM FEHLER" 64 "Bremse ueberhitzt !" 65 "Bremse haelt !" 66 "ESP PASSIV !" 67 "ACC_anfahrbereit" 68 "Gang_einlegen" 69 "Rechtsueberholen_verhindert" 70 "Linksueberholen_verhindert" 71 "Achtung_Geschwindigkeitsueberschreitung" 72 "Tempolimit_und_Kurvenassistent_nicht_verfuegbar" ;
VAL_ 780 ACC_Wunschgeschw_erreicht 0 "Wunschgeschwindigkeit_nicht_erreicht" 1 "Wunschgeschwindigkeit_erreicht" ;
VAL_ 780 ACC_Typ_Tachokranz_unten 0 "LEDs_an" 1 "LEDs_aus" ;
VAL_ 780 ACC_Status_Anzeige 0 "ACC_GRA_Hauptschalter_aus" 1 "ACC_in_Init_nicht_bei_GRA" 2 "ACC_GRA_passiv" 3 "ACC_GRA_aktiv" 4 "ACC_GRA_im_Hintergrund_uebertreten" 5 "ACC_GRA_Abschaltreaktion" 6 "ACC_reversibel_aus_nicht_bei_GRA" 7 "ACC_GRA_irreversibel_aus" ;
VAL_ 804 ACC_Texte_Sekundaeranz 0 "keine_Anzeige" 1 "Zielfahrzeug_erkannt" 2 "Rechtskurve_voraus" 3 "Linkskurve_voraus" 4 "Tempolimit_voraus" 5 "Sensorsicht" 6 "Anfahrbereit" 7 "Tempolimit_erkannt" 8 "Kreuzung_voraus" 9 "Kreisverkehr_voraus" ;
VAL_ 804 ACC_Texte_Zusatzanz 0 "keine_Anzeige" 1 "ACC_AUS" 2 "ACC_BEREIT" 3 "UEBERTRETEN" 4 "ABSTAND" 5 "DISTANZ_1" 6 "DISTANZ_2" 7 "DISTANZ_3" 8 "DISTANZ_4" 9 "DISTANZ_1__dyn" 10 "DISTANZ_2__dyn" 11 "DISTANZ_3__dyn" 12 "DISTANZ_4__dyn" 13 "DISTANZ_1__stand" 14 "DISTANZ_2__stand" 15 "DISTANZ_3__stand" 16 "DISTANZ_4__stand" 17 "DISTANZ_1__comf" 18 "DISTANZ_2__comf" 19 "DISTANZ_3__comf" 20 "DISTANZ_4__comf" 21 "DISTANZ_1__efficiency" 22 "DISTANZ_2__efficiency" 23 "DISTANZ_3__efficiency" 24 "DISTANZ_4__efficiency" 25 "DISTANZ_5" 26 "DISTANZ_5__dyn" 27 "DISTANZ_5__stand" 28 "DISTANZ_5__comf" 29 "DISTANZ_5__efficiency" 30 "ACHTUNG" 31 "Abstandsanzeige" 32 "Abstandsanz_Warnung_aktiviert" ;
VAL_ 804 ACC_Status_Zusatzanz 0 "keine Anzeige" 1 "Bild 1 (Fzg. Silhouette, typ. farblos)" 2 "Bild 2 (Fzg. Farbe 1, typ. grau)" 3 "Bild 3 (Fzg. Farbe 2, typ. rot)" 4 "Bild 4 (Symbol 1 ACCplus, typ. Doppelfzg. gelb)" 5 "Bild 5 (Symbol 2 ACCplus, typ. Doppelfzg. grau)" 6 "Bild 6 (Fzg. Farbe 2, typ. rot) mit Priorität im Kombi (Pop-up)" ;
VAL_ 804 ACC_Texte 0 "keine_Anzeige" 1 "ACC_nicht_verfuegbar" 2 "ACC_und_AWV_nicht_verfuegbar" 3 "ACC_keine_Sensorsicht" 4 "ACC_und_AWV_keine_Sensorsicht" 5 "ACC_Steigung_zu_gross" 6 "ACC_nur_in_Fahrstufe_verfuegbar" 7 "ACC_Parkbremse_betaetigt" 8 "ACC_ESP_Eingriff" 9 "ACC_Bitte_uebernehmen" 10 "ACC_HDC_betaetigt" 11 "ACC_Geschwindigkeitsgrenze" 12 "ACC_Schalthebelposition" 13 "ACC_Drehzahl" 14 "ACC_Kupplung_betaetigt" 15 "ACC_Aktivierverhinderung" 16 "ACC_Abschaltung" 17 "ACC_Parkassistent_aktiv" 18 "ACC_ESC_aus" 19 "ACC_Charisma_Modus_inkompatibel" 20 "ACC_Stehendes_Objekt_voraus" 21 "ACA_Fahreruebernahme" 22 "ACA_Querfuehrung_nicht_verfuegbar" ;
VAL_ 804 ACC_Texte_braking_guard 0 "keine_Anzeige" 1 "AWV_aus" 2 "AWV_Warnung" 3 "AWV_Demomodus" 4 "AWV_Systemstoerung" 5 "AWV_Eingriff" 6 "AWV_Vorwarnung_aus" 7 "AWV_keine_Sensorsicht" ;
VAL_ 804 ACC_Warnhinweis 0 "kein_Warnhinweis" 1 "Warnhinweis" ;
VAL_ 804 ACC_Zeitluecke_Abstandswarner 61 "Freifahrt" 62 "nicht_definiert" 63 "keine_Anzeige" ;
VAL_ 804 ACC_Abstand_Abstandswarner 509 "Freifahrt" 510 "nicht_definiert" 511 "keine_Anzeige" ;
VAL_ 804 ACC_Tempolimit 0 "keine_Anzeige" 1 "5_zulHoechstgeschw" 2 "7_zulHoechstgeschw" 3 "10_zulHoechstgeschw" 4 "15_zulHoechstgeschw" 5 "20_zulHoechstgeschw" 6 "25_zulHoechstgeschw" 7 "30_zulHoechstgeschw" 8 "35_zulHoechstgeschw" 9 "40_zulHoechstgeschw" 10 "45_zulHoechstgeschw" 11 "50_zulHoechstgeschw" 12 "55_zulHoechstgeschw" 13 "60_zulHoechstgeschw" 14 "65_zulHoechstgeschw" 15 "70_zulHoechstgeschw" 16 "75_zulHoechstgeschw" 17 "80_zulHoechstgeschw" 18 "85_zulHoechstgeschw" 19 "90_zulHoechstgeschw" 20 "95_zulHoechstgeschw" 21 "100_zulHoechstgeschw" 22 "110_zulHoechstgeschw" 23 "120_zulHoechstgeschw" 24 "130_zulHoechstgeschw" 25 "140_zulHoechstgeschw" 26 "150_zulHoechstgeschw" 27 "160_zulHoechstgeschw" 28 "200_zulHoechstgeschw" 30 "250_zulHoechstgeschw" 31 "Ende_zulHoechstgeschw" ;
VAL_ 804 ACC_Charisma_FahrPr 0 "keine_Funktion" 1 "Programm_1" 2 "Programm_2" 3 "Programm_3" 4 "Programm_4" 5 "Programm_5" 6 "Programm_6" 7 "Programm_7" 8 "Programm_8" 9 "Programm_9" 10 "Programm_10" 11 "Programm_11" 12 "Programm_12" 13 "Programm_13" 14 "Programm_14" 15 "Programm_15" ;
VAL_ 804 ACC_Charisma_Status 0 "Init" 1 "verfuegbar" 2 "nicht_verfuegbar" 3 "asynchron_durch_Fahrerwunsch" ;
VAL_ 804 ACC_Texte_Abstandswarner 0 "keine_Anzeige" 1 "Systemstoerung" 2 "keine_Sensorsicht" 3 "zurzeit_eingeschraenkt" ;
VAL_ 302 ACC_Anhalteweg 2046 "Neutralwert" 2047 "Fehler" ;
VAL_ 302 ACC_Anhalten 0 "kein_Anhalten_gewuenscht" 1 "Anhalten_gewuenscht" ;
VAL_ 302 ACC_Freilauf_Anf 0 "keine Freilauf-Anforderung" 1 "Freilauf-Anforderung" ;
VAL_ 302 ACC_Freilauf_Info 0 "Freilauf_freigegeben" 1 "kein_Uebergang_in_Freilauf_zulaessig" 2 "Freilauf_nicht_freigegeben" 3 "Freilauf_Anforderung" ;
VAL_ 302 ACC_Anforderung_HMS 0 "keine_Anforderung" 1 "halten" 2 "parken" 3 "halten_Standby" 4 "anfahren" 5 "Loesen_ueber_Rampe" ;
VAL_ 302 ACC_Anfahren 0 "keine_Anforderung_Anfahren" 1 "Anforderung_Anfahren" ;
VAL_ 302 ACC_Folgebeschl 254 "Neutralwert" ;
VAL_ 302 ACC_Sollbeschleunigung_02 2046 "Neutralwert" 2047 "Fehler" ;
VAL_ 391 MO_Waehlpos 2 "P" 3 "R" 4 "N" 5 "D" 6 "D" ;
VAL_ 391 EV_Rekuperationsstufe 0 "default" 1 "B1" 2 "B2" 3 "B3" ;
VAL_ 870 Fast_Send_Rate_Active 0 "1 Hz" 1 "50 Hz" ;
VAL_ 988 EPB_Status 0 "offen" 1 "geschlossen_Parken" 2 "teilgespannt_Halten" 3 "im_Lauf_oeffnen" 4 "im_Lauf_schliessen" 5 "tbd" 6 "Init" 7 "unbekannt";
VAL_ 988 GE_Fahrstufe 0 "Zwischenstellung" 1 "Init" 5 "P" 6 "R" 7 "N" 8 "D" 9 "S" 10 "E" 13 "T" 14 "T" 15 "Fehler";
VAL_ 1720 KBI_Variante_USA 0 "keine USA-Variante" 1 "USA-Variante" ;
VAL_ 1720 KBI_Variante 0 "Zeiger Kombiinstrument" 1 "Volldisplay Kombiinstrument" ;
VAL_ 1720 KBI_BCmE_aktiv 0 "Anzeige_nicht_aktiv" 1 "Anzeige_aktiv" ;
VAL_ 1720 KBI_Sparhinweis_quittiert 0 "nicht_quittiert" 1 "quittiert" ;
VAL_ 1720 KBI_Tankfuellstand_Prozent 126 "Init" 127 "Fehler" ;
VAL_ 1720 KBI_Nachtanken_erkannt 0 "Geberbetrieb" 1 "Nachtankmodus" ;
VAL_ 1720 KBI_Tankinhalt_hochaufl 16382 "Init" 16383 "Fehler" ;
VAL_ 1720 KBI_Max_Tankinhalt 254 "Init" 255 "Fehler" ;
VAL_ 1122 PSD_Segment_ID 0 "keine Segmentinformationen vorhanden" 1 "Fehlerwert";
VAL_ 1122 PSD_Vorgaenger_Segment_ID 0 "keine Segmentinformation vorhanden" 1 "Fehlerwert";
VAL_ 1122 PSD_Strassenkategorie 0 "Rest_Feldweg_Schotterweg_Privatweg" 1 "Ortsstraߥ" 2 "Kreisstraߥ" 3 "Landstraߥ" 4 "Bundesstraߥ" 5 "Autobahn" 7 "Init";
VAL_ 1122 PSD_Endkruemmung 255 "Gerade";
VAL_ 1122 PSD_Endkruemmung_Vorz 0 "Kruemmung_positiv" 1 "Kruemmung_negativ";
VAL_ 1122 PSD_Idenditaets_ID 0 "keine_Segment_Informationen_vorhanden" 1 "Fehler";
VAL_ 1122 PSD_ADAS_Qualitaet 0 "keine_ADAS_Qualitaet" 1 "ADAS_Qualitaet";
VAL_ 1122 PSD_wahrscheinlichster_Pfad 0 "Pfad_mit_geringer_Wahrscheinlichkeit" 1 "wahrscheinlichster_Pfad";
VAL_ 1122 PSD_Geradester_Pfad 0 "nicht_geradester_PFad" 1 "geradester_Pfad";
VAL_ 1122 PSD_Fahrspuren_Anzahl 0 "Einbahnstrasse_in_falsche_Richtung" 1 "eine_Fahrspur" 2 "zwei_Fahrspuren" 3 "drei_Fahrspuren" 4 "vier_Fahrspuren" 5 "fuenf_Fahrspuren" 6 "sechs_Fahrspuren" 7 "mehr_als_sechs_Fahrspuren";
VAL_ 1122 PSD_Bebauung 0 "ausserhalb_bebauten_Gebietes" 1 "innerhalb_bebauten_Gebietes";
VAL_ 1122 PSD_Segment_Komplett 0 "Segment_Attribute_nicht_komplett" 1 "Segment_Attribute_komplett";
VAL_ 1122 PSD_Rampe 0 "Strasse_mit_Gegenverkehr" 1 "Auffahrt_Einbahnstr" 2 "Abfahrt_Einbahnstr" 3 "Einbahnstrasse";
VAL_ 1122 PSD_Anfangskruemmung 255 "Gerade";
VAL_ 1122 PSD_Anfangskruemmung_Vorz 0 "positiv" 1 "negativ";
VAL_ 1122 PSD_Abzweigerichtung 0 "rects_abzweigende_Strasse" 1 "links_abzweigende_Strasse";
VAL_ 1123 PSD_Pos_Segment_ID 0 "keine Position gegeben" 1 "Fehlerwert";
VAL_ 1123 PSD_Pos_Standort_Eindeutig 0 "mehrdeutiger_Standort" 1 "eindeutiger_Standort";
VAL_ 1123 PSD_Pos_Fehler_Laengsrichtung 0 "Init" 1 "< 2m" 2 "< 5m" 3 "< 10m" 4 "< 20m" 5 "< 50m" 6 "> 50m" 7 "Off-Road";
VAL_ 1123 PSD_Pos_Fahrspur 0 "unbekannt" 1 "Erste_Spur_von_rechts" 2 "Zweite_Spur_von_rechts" 3 "Dritte_Spur_von_rechts" 4 "Vierte_Spur_von_rechts" 5 "Fuenfte_Spur_von_rechts" 6 "Sechte_Spur_von_rechts" 7 "Siebte_oder_weitere_Spur_von_rechts";
VAL_ 1123 PSD_Attribut_Segment_ID_05 0 "keine_Segment_Information" 1 "Fehler";
VAL_ 1123 PSD_Attribut_1_ID 0 "keine_Information";
VAL_ 1123 PSD_Attribut_2_ID 0 "keine_Information";
VAL_ 1123 PSD_Attribute_Komplett_05 0 "Attribute_nicht_komplett" 1 "Attribute_komplett";
VAL_ 1124 PSD_06_Mux 0 "Init";
VAL_ 1124 PSD_Sys_Segment_ID 0 "keine Segmentinformationen vorhanden" 1 "nicht zulaessig";
VAL_ 1124 PSD_Sys_Geschwindigkeit_Einheit 0 "km/h" 1 "mph";
VAL_ 1124 PSD_Sys_Verkehrsrichtung 0 "Rechtsverkehr" 1 "Linksverkehr";
VAL_ 1124 PSD_Sys_Geometrieguete 0 "Geringe_Guete" 1 "tbd" 2 "tbd" 3 "Hohe_Guete";
VAL_ 1124 PSD_Sys_Mapmatchingguete 0 "geringe_Guete" 1 "res" 2 "res" 3 "hohe_Guete";
VAL_ 1124 PSD_Sys_Alter_Karte 0 "kleiner_1_Jahr" 1 "1_Jahr" 2 "2_Jahre" 3 "3_Jahre" 4 "4_Jahre" 5 "5_Jahre" 6 "6_Jahre" 7 "groesser_7_Jahre";
VAL_ 1124 PSD_Sys_Zielfuehrung 0 "Zielfuehrung nicht aktiv" 1 "Zielfuehrung aktiv";
VAL_ 1124 PSD_Sys_US_State 0 "kein_US_State" 1 "Alabama" 2 "Alaska" 3 "Arkansas" 4 "Arizona" 5 "California" 6 "Colorado" 7 "Conneticut" 8 "District_of_Columbia" 9 "Delaware" 10 "Florida" 11 "Georgia" 12 "Hawaii" 13 "Idaho" 14 "Illinois" 15 "Iowa" 16 "Indiana" 17 "Kansas" 18 "Kentucky" 19 "Louisiana" 20 "Massachusetts" 21 "Maryland" 22 "Maine" 23 "Michigan" 24 "Minnesota" 25 "Missouri" 26 "Mississippi" 27 "Montana" 28 "North_Carolina" 29 "North_Dakota" 30 "Nebraska" 31 "Nevada" 32 "New_Hampshire" 33 "New_Jersey" 34 "New_Mexico" 35 "New_York" 36 "Ohio" 37 "Oklahoma" 38 "Oregon" 39 "Pennsylvania" 40 "Puerto_Rico" 41 "Rhode_Island" 42 "South_Carolina" 43 "South_Dakota" 44 "Tennessee" 45 "Texas" 46 "Utah" 47 "Virginia" 48 "Virgin_Islands" 49 "Vermont" 50 "Washington" 51 "Wisconsin" 52 "West_Virginia" 53 "Wyoming";
VAL_ 1124 PSD_Sys_Quali_verfuegbar 0 "Qualitaetskriterien_nicht_verfuegbar" 1 "Qualitaetskriterien_verfuegbar";
VAL_ 1124 PSD_Sys_Zielfuehrung_geaendert 0 "Zielfuehrung_nicht_geaendert" 1 "Zielfuehrung_geaendert";
VAL_ 1124 PSD_Sys_Geometrieguete_erweitert 0 "Init";
VAL_ 1124 PSD_Attribut_Segment_ID 0 "keine_Segment_Information_vorhanden" 1 "Fehler";
VAL_ 1124 PSD_Attribut_3_ID 0 "keine_Information";
VAL_ 1124 PSD_Attribut_4_ID 0 "keine_Information";
VAL_ 1124 PSD_Attribut_5_ID 0 "keine_Information";
VAL_ 1124 PSD_Attribute_Komplett_06 0 "Attribute_nicht_komplett" 1 "Attribute_komplett";
VAL_ 1124 PSD_Ges_Segment_ID 0 "keine Segmentinformationen vorhanden" 1 "nicht zulaessig";
VAL_ 1124 PSD_Ges_Geschwindigkeit 0 "Kein Geschwindigkeitsgebot" 1 "0 km/h < v_max <  5 km/h" 2 "5 km/h < v_max < 10km/h" 3 "10 km/h < v_max < 15 km/h" 4 "15 km/h < v_max < 20 km/h" 5 "20 km/h < v_max < 25 km/h" 6 "25 km/h < v_max < 30 km/h" 7 "30 km/h < v_max < 35 km/h" 8 "35 km/h < v_max < 40 km/h" 9 "40 km/h < v_max < 45 km/h" 10 "45 km/h < v_max < 50 km/h" 11 "50 km/h < v_max < 60 km/h" 12 "60 km/h < v_max < 70 km/h" 13 "70 km/h < v_max < 80 km/h" 14 "80 km/h < v_max < 90 km/h" 15 "90 km/h < v_max < 100 km/h" 16 "100 km/h < v_max < 110 km/h" 17 "110 km/h < v_max < 120 km/h" 18 "120 km/h < v_max < 130 km/h" 19 "130 km/h < v_max < 140 km/h" 20 "140 km/h < v_max < 150 km/h" 21 "150 km/h < v_max < 160 km/h" 22 "160 km/h < v_max" 23 "Geschwindigkeitsgebot aufgehoben" 24 "..0x1F ungültig";
VAL_ 1124 PSD_Ges_Typ 0 "Geschw_Klasse_des_Kartendatensuppliers" 1 "Explizit_abgeleiteten_Begrenzung" 2 "Durch_Gesetzg_vorgeg_allgem_Gebot_fuer_uebertr_Rahmenbed" 3 "Init";
VAL_ 1124 PSD_Ges_Spur_Geschw_Begrenzung 0 "Gebot_fuer_alle_spuren_gueltig";
VAL_ 1124 PSD_Ges_Geschwindigkeit_Gespann 0 "alle Fahrzeuge" 1 "PKW mit Gespann" 2 "LKW, Busse, etc.";
VAL_ 1124 PSD_Ges_Geschwindigkeit_Witter 0 "Witterungsunabh䮧ig" 1 "N䳳e, Regen, Niederschlag" 2 "Gl䴴e" 3 "Nebel";
VAL_ 1124 PSD_Ges_Geschwindigkeit_Tag_Anf 0 "kein Beginn definiert" 1 "Montag" 2 "Dienstag" 3 "Mittwoch" 4 "Donnerstag" 5 "Freitag" 6 "Samstag" 7 "Sonntag";
VAL_ 1124 PSD_Ges_Geschwindigkeit_Tag_Ende 0 "kein Ende definiert" 1 "Montag" 2 "Dienstag" 3 "Mittwoch" 4 "Donnerstag" 5 "Freitag" 6 "Samstag" 7 "Sonntag";
VAL_ 1124 PSD_Ges_Geschwindigkeit_Std_Anf 25 "kein Beginn für stundenweise Einschr䮫ungen";
VAL_ 1124 PSD_Ges_Geschwindigkeit_Std_Ende 25 "kein Ende für stundenweise Einschr䮫ungen";
VAL_ 1124 PSD_Ges_Ueberholverbot 0 "kein ܢerholverbot" 1 "alle Fahrzeuge" 2 "ܢerholverbot für PKW mit Gespann" 3 "ܢerholverbot für LKW, Busse, etc.";
VAL_ 1124 PSD_Ges_Wechselverkehrszeichen 0 "Kein Wechselverkehrszeichen" 1 "Wechselverkehrszeichen links" 2 "Wechselverkehrszeichen rechts" 3 "Wechselverkehrszeichen links und rechts" 4 "Wechselverkerhszeichen über der Fahrbahn";
VAL_ 1124 PSD_Wechselverkehrszeichen_Typ 0 "kein_Wechselverkehrszeichen" 1 "LED_Wechselverkehrszeichen" 2 "nicht_LED_Wechselverkehrszeichen";
VAL_ 1124 PSD_Ges_Gesetzlich_Kategorie 0 "kein_legales_Verbot" 1 "innerorts" 2 "ausserorts" 3 "Autobahn";
VAL_ 1124 PSD_Ges_Gesetzlich_Zusatz 0 "kein_Zusatz_zu_legalem_Gebot" 1 "Anhaenger_Klasse_1" 2 "Anhaenger_Klasse_2";
VAL_ 1124 PSD_Ges_Verkehrszeichen_Quelle 0 "VZA_kein_Onlinedienst" 1 "nur_VZA" 2 "nur_VZO" 3 "VZA_und_VZO";
VAL_ 1124 PSD_Ges_Attribute_Komplett 0 "Attribute_nicht_komplett" 1 "Attribute_komplett";
VAL_ 1124 PSD_Baum_Laenge_VZ 0 "Ost" 1 "West";
VAL_ 1124 PSD_Baum_Breite_VZ 0 "Nord" 1 "Sued";
VAL_ 1124 PSD_Steigung_1_Segment_ID 0 "keine_Segment_Information_vorhanden" 1 "Fehler";
VAL_ 1124 PSD_Steigung_1_A_Steigung 126 "mehr_als_15_Prozent" 127 "Steigung_unbekannt";
VAL_ 1124 PSD_Steigung_1_A_Vorz 0 "Gefaelle" 1 "Steigung";
VAL_ 1124 PSD_Steigung_1_B_Steigung 126 "mehr_als_15_Prozent" 127 "Steigung_unbekannt";
VAL_ 1124 PSD_Steigung_1_B_Vorz 0 "Gefaelle" 1 "Steigung";
VAL_ 1124 PSD_Steigung_1_Attribute_kompl 0 "Steigungen_nicht_komplett" 1 "Steigungen_komplett";
VAL_ 1124 PSD_Steigung_2_Segment_ID 0 "keine_Segment_Information_vorhanden" 1 "Fehler";
VAL_ 1124 PSD_Steigung_2_Steigung 126 "mehr_als_15_Prozent" 127 "Steigung_unbekannt";
VAL_ 1124 PSD_Steigung_2_Vorz 0 "Gefaelle" 1 "Steigung";
VAL_ 1124 PSD_Steigung_2_Attribute_kompl 0 "Steigungen_nicht_komplett" 1 "Steigungen_komplett";
CM_ SG_ 919 LDW_Frueh_Spaet "VW LDW_Frueh_Spaet: the driver's early/late lane-departure warning setting. Replaces the old LDW_SW_Warnung_links/rechts (bits 14/15), which VW removed for MQB.";
VAL_ 919 LDW_Frueh_Spaet 0 "frueh_frueh_aktiv" 1 "frueh_spaet_aktiv" 2 "spaet_spaet_aktiv" 3 "Fehler";
